AUTOSAR XML (schema 00044)
package /E40_Platform_System_SystemPackage/Components
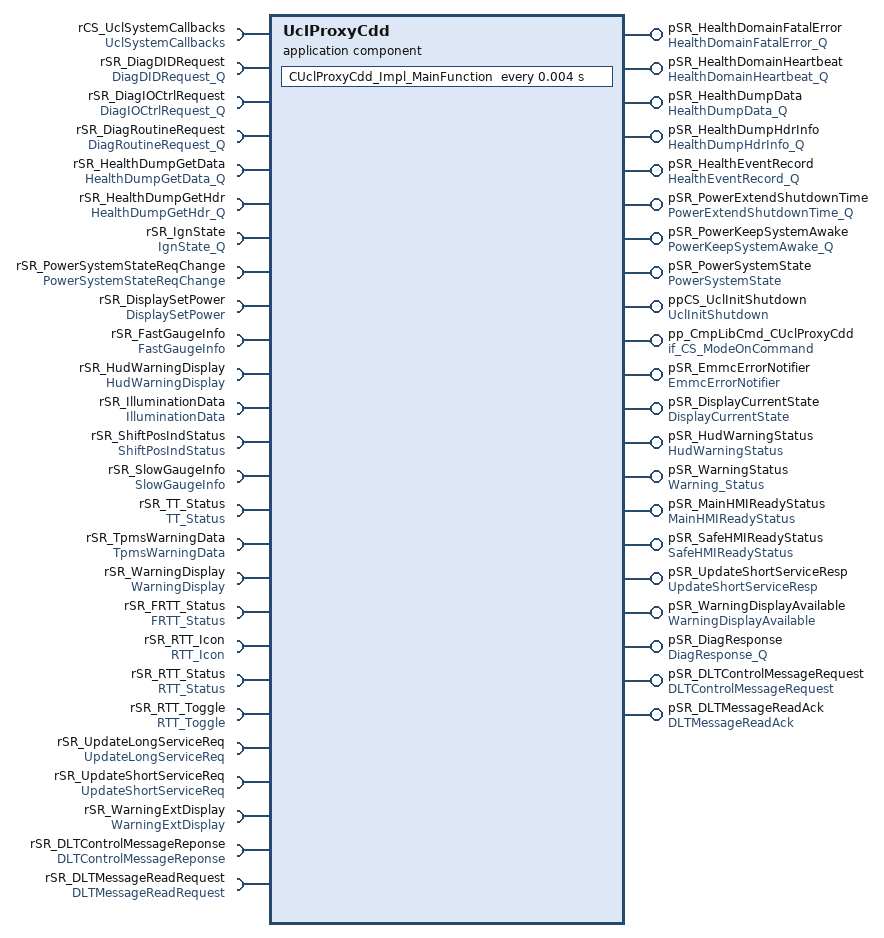
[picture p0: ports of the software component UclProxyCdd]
  application sw component type UclProxyCdd
    10 x provide port:
      pSR_HealthDomainFatalError: queued-sender-com-spec=HealthDomainFatalErrorData, provided-interface=HealthDomainFatalError_Q
      pSR_HealthDomainHeartbeat: queued-sender-com-spec=HealthDomainHeartbeatData, provided-interface=HealthDomainHeartbeat_Q
      pSR_HealthDumpData: queued-sender-com-spec=HealthDumpDataData, provided-interface=HealthDumpData_Q
      pSR_HealthDumpHdrInfo: queued-sender-com-spec=HealthDumpHdrInfoData, provided-interface=HealthDumpHdrInfo_Q
      pSR_HealthEventRecord: queued-sender-com-spec=HealthEventRecordData, provided-interface=HealthEventRecord_Q
      pSR_PowerExtendShutdownTime: queued-sender-com-spec=PowerExtendShutdownTimeData, provided-interface=PowerExtendShutdownTime_Q
      pSR_PowerKeepSystemAwake: queued-sender-com-spec=PowerKeepSystemAwakeData, provided-interface=PowerKeepSystemAwake_Q
      pSR_PowerSystemState: nonqueued-sender-com-spec{data-element=PowerSystemStateData, init-value=constant-reference=UclProxyCddPowerSystemStateDataValue0}, provided-interface=PowerSystemState
      ppCS_UclInitShutdown: provided-com-specs=[{operation=Impl_Initialize, queue-length=1}, {operation=Impl_Shutdown, queue-length=1}], provided-interface=UclInitShutdown
      pp_CmpLibCmd_CUclProxyCdd: server-com-spec{operation=Impl_OnCommand, queue-length=1}, provided-interface=if_CS_ModeOnCommand
    8 x require port:
      rCS_UclSystemCallbacks: required-com-specs=[ErrorNotification, LinkStatusChanged], required-interface=UclSystemCallbacks
      rSR_DiagDIDRequest: queued-receiver-com-spec{data-element=DiagDIDRequestData, queue-length=2}, required-interface=DiagDIDRequest_Q
      rSR_DiagIOCtrlRequest: queued-receiver-com-spec{data-element=DiagIOCtrlRequestData, queue-length=2}, required-interface=DiagIOCtrlRequest_Q
      rSR_DiagRoutineRequest: queued-receiver-com-spec{data-element=DiagRoutineRequestData, queue-length=2}, required-interface=DiagRoutineRequest_Q
      rSR_HealthDumpGetData: queued-receiver-com-spec{data-element=HealthDumpGetDataData, queue-length=1}, required-interface=HealthDumpGetData_Q
      rSR_HealthDumpGetHdr: queued-receiver-com-spec{data-element=HealthDumpGetHdrData, queue-length=1}, required-interface=HealthDumpGetHdr_Q
      rSR_IgnState: queued-receiver-com-spec{data-element=IgnStateData, queue-length=5}, required-interface=IgnState_Q
      rSR_PowerSystemStateReqChange: nonqueued-receiver-com-spec{data-element=PowerSystemStateReqChangeData, filter=data-filter-type=ALWAYS, init-value=constant-reference=UclProxyCddPowerSystemStateReqChangeDataValue0}, required-interface=PowerSystemStateReqChange
    provide port pSR_EmmcErrorNotifier: nonqueued-sender-com-spec{data-element=EmmcErrorNotifierData, init-value=constant-reference=UclProxyCddEmmcErrorNotifierDataValue0}, provided-interface=EmmcErrorNotifier
    provide port pSR_DisplayCurrentState: nonqueued-sender-com-spec{data-element=DisplayCurrentStateData, init-value=constant-reference=UclProxyCddDisplayCurrentStateDataValue0}, provided-interface=DisplayCurrentState
    require port rSR_DisplaySetPower: nonqueued-receiver-com-spec{data-element=DisplaySetPowerData, filter=data-filter-type=ALWAYS, init-value=constant-reference=UclProxyCddDisplaySetPowerDataValue0}, required-interface=DisplaySetPower
    provide port pSR_HudWarningStatus: nonqueued-sender-com-spec{data-element=HudWarningStatusData, init-value=constant-reference=UclProxyCddHudWarningStatusDataValue0}, provided-interface=HudWarningStatus
    provide port pSR_WarningStatus: nonqueued-sender-com-spec{data-element=WarningStatusData, init-value=constant-reference=UclProxyCddWarningStatusDataValue0}, provided-interface=Warning_Status
    8 x require port:
      rSR_FastGaugeInfo: nonqueued-receiver-com-spec{data-element=FastGaugeInfoData, filter=data-filter-type=ALWAYS, init-value=constant-reference=SFastGaugeInfo_InitValue}, required-interface=FastGaugeInfo
      rSR_HudWarningDisplay: nonqueued-receiver-com-spec{data-element=HudWarningDisplayData, filter=data-filter-type=ALWAYS, init-value=constant-reference=UclProxyCddHudWarningDisplayDataValue0}, required-interface=HudWarningDisplay
      rSR_IlluminationData: nonqueued-receiver-com-spec{data-element=IlluminationDataData, filter=data-filter-type=ALWAYS, init-value=constant-reference=UclProxyCddIlluminationDataDataValue0}, required-interface=IlluminationData
      rSR_ShiftPosIndStatus: nonqueued-receiver-com-spec{data-element=ShiftPosIndStatusData, filter=data-filter-type=ALWAYS, init-value=constant-reference=UclProxyCddShiftPosIndStatusDataValue0}, required-interface=ShiftPosIndStatus
      rSR_SlowGaugeInfo: nonqueued-receiver-com-spec{data-element=SlowGaugeInfoData, filter=data-filter-type=ALWAYS, init-value=constant-reference=UclProxyCddSlowGaugeInfoDataValue0}, required-interface=SlowGaugeInfo
      rSR_TT_Status: nonqueued-receiver-com-spec{data-element=TT_StatusData, filter=data-filter-type=ALWAYS, init-value=constant-reference=UclProxyCddTT_StatusDataValue0}, required-interface=TT_Status
      rSR_TpmsWarningData: nonqueued-receiver-com-spec{data-element=TpmsWarningDataData, filter=data-filter-type=ALWAYS, init-value=constant-reference=UclProxyCddTpmsWarningDataDataValue0}, required-interface=TpmsWarningData
      rSR_WarningDisplay: nonqueued-receiver-com-spec{data-element=WarningDisplayData, filter=data-filter-type=ALWAYS, init-value=constant-reference=UclProxyCddWarningDisplayDataValue0}, required-interface=WarningDisplay
    4 x provide port:
      pSR_MainHMIReadyStatus: queued-sender-com-spec=MainHMIReadyStatusData, provided-interface=MainHMIReadyStatus
      pSR_SafeHMIReadyStatus: queued-sender-com-spec=SafeHMIReadyStatusData, provided-interface=SafeHMIReadyStatus
      pSR_UpdateShortServiceResp: queued-sender-com-spec=UpdateShortServiceRespData, provided-interface=UpdateShortServiceResp
      pSR_WarningDisplayAvailable: nonqueued-sender-com-spec{data-element=WarningDisplayAvailableData, init-value=constant-reference=UclProxyCddWarningDisplayAvailableDataValue0}, provided-interface=WarningDisplayAvailable
    7 x require port:
      rSR_FRTT_Status: nonqueued-receiver-com-spec{data-element=FRTT_StatusData, filter=data-filter-type=ALWAYS, init-value=constant-reference=UclProxyCddFRTT_StatusDataValue0}, required-interface=FRTT_Status
      rSR_RTT_Icon: nonqueued-receiver-com-spec{data-element=RTT_IconData, filter=data-filter-type=ALWAYS, init-value=constant-reference=UclProxyCddRTT_IconDataValue0}, required-interface=RTT_Icon
      rSR_RTT_Status: nonqueued-receiver-com-spec{data-element=RTT_StatusData, filter=data-filter-type=ALWAYS, init-value=constant-reference=UclProxyCddRTT_StatusDataValue0}, required-interface=RTT_Status
      rSR_RTT_Toggle: nonqueued-receiver-com-spec{data-element=RTT_ToggleData, filter=data-filter-type=ALWAYS, init-value=constant-reference=UclProxyCddRTT_ToggleDataValue0}, required-interface=RTT_Toggle
      rSR_UpdateLongServiceReq: queued-receiver-com-spec{data-element=UpdateLongServiceReqData, queue-length=2}, required-interface=UpdateLongServiceReq
      rSR_UpdateShortServiceReq: queued-receiver-com-spec{data-element=UpdateShortServiceReqData, queue-length=2}, required-interface=UpdateShortServiceReq
      rSR_WarningExtDisplay: nonqueued-receiver-com-spec{data-element=WarningExtDisplayData, filter=data-filter-type=ALWAYS, init-value=constant-reference=UclProxyCddWarningExtDisplayDataValue0}, required-interface=WarningExtDisplay
    provide port pSR_DiagResponse: queued-sender-com-spec=DiagResponseData, provided-interface=DiagResponse_Q
    provide port pSR_DLTControlMessageRequest: nonqueued-sender-com-spec{data-element=DLTControlMessageRequestData, init-value=constant-reference=UclProxyCddDLTControlMessageRequestDataValue0}, provided-interface=DLTControlMessageRequest
    provide port pSR_DLTMessageReadAck: nonqueued-sender-com-spec{data-element=DLTMessageReadAckData, init-value=constant-reference=UclProxyCddDLTMessageReadAckDataValue0}, provided-interface=DLTMessageReadAck
    require port rSR_DLTControlMessageReponse: nonqueued-receiver-com-spec{data-element=DLTControlMessageReponseData, init-value=constant-reference=UclProxyCddDLTControlMessageReponseDataValue0}, required-interface=DLTControlMessageReponse
    require port rSR_DLTMessageReadRequest: nonqueued-receiver-com-spec{data-element=DLTMessageReadRequestData, init-value=constant-reference=UclProxyCddDLTMessageReadRequestDataValue0}, required-interface=DLTMessageReadRequest
    behavior IB_UclProxyCdd
      operation invoked event OIE_ppCS_UclInitShutdown_CUclProxyCdd_Impl_InitializeTrigByImpl_Initialize: start-on-event=CUclProxyCdd_Impl_Initialize, operation=ppCS_UclInitShutdown.Impl_Initialize
      timing event TECUclProxyCdd_Impl_MainFunction: start-on-event=CUclProxyCdd_Impl_MainFunction, period=0.004
      operation invoked event OIE_pp_CmpLibCmd_CUclProxyCdd_CUclProxyCdd_Impl_OnCommandTrigByImpl_OnCommand: start-on-event=CUclProxyCdd_Impl_OnCommand, operation=pp_CmpLibCmd_CUclProxyCdd.Impl_OnCommand
      operation invoked event OIE_ppCS_UclInitShutdown_CUclProxyCdd_Impl_ShutdownTrigByImpl_Shutdown: start-on-event=CUclProxyCdd_Impl_Shutdown, operation=ppCS_UclInitShutdown.Impl_Shutdown
      22 x data received event:
        DREOnDre_HealthDumpGetDataTrigByHealthDumpGetDataData: start-on-event=OnDre_HealthDumpGetData, data=rSR_HealthDumpGetData.HealthDumpGetDataData
        DREOnDre_HealthDumpGetHdrTrigByHealthDumpGetHdrData: start-on-event=OnDre_HealthDumpGetHdr, data=rSR_HealthDumpGetHdr.HealthDumpGetHdrData
        DREOnDre_PowerSystemStateReqChangeTrigByPowerSystemStateReqChangeData: start-on-event=OnDre_PowerSystemStateReqChange, data=rSR_PowerSystemStateReqChange.PowerSystemStateReqChangeData
        DREOnDre_DisplaySetPowerTrigByDisplaySetPowerData: start-on-event=OnDre_DisplaySetPower, data=rSR_DisplaySetPower.DisplaySetPowerData
        DREOnDre_FRTT_StatusTrigByFRTT_StatusData: start-on-event=OnDre_FRTT_Status, data=rSR_FRTT_Status.FRTT_StatusData
        DREOnDre_FastGaugeInfoTrigByFastGaugeInfoData: start-on-event=OnDre_FastGaugeInfo, data=rSR_FastGaugeInfo.FastGaugeInfoData
        DREOnDre_RTT_IconTrigByRTT_IconData: start-on-event=OnDre_RTT_Icon, data=rSR_RTT_Icon.RTT_IconData
        DREOnDre_RTT_StatusTrigByRTT_StatusData: start-on-event=OnDre_RTT_Status, data=rSR_RTT_Status.RTT_StatusData
        DREOnDre_RTT_ToggleTrigByRTT_ToggleData: start-on-event=OnDre_RTT_Toggle, data=rSR_RTT_Toggle.RTT_ToggleData
        DREOnDre_ShiftPosIndStatusTrigByShiftPosIndStatusData: start-on-event=OnDre_ShiftPosIndStatus, data=rSR_ShiftPosIndStatus.ShiftPosIndStatusData
        DREOnDre_SlowGaugeInfoTrigBySlowGaugeInfoData: start-on-event=OnDre_SlowGaugeInfo, data=rSR_SlowGaugeInfo.SlowGaugeInfoData
        DREOnDre_TT_StatusTrigByTT_StatusData: start-on-event=OnDre_TT_Status, data=rSR_TT_Status.TT_StatusData
        DREOnDre_WarningDisplayTrigByWarningDisplayData: start-on-event=OnDre_WarningDisplay, data=rSR_WarningDisplay.WarningDisplayData
        DREOnDre_DiagDIDRequestTrigByDiagDIDRequestData: start-on-event=OnDre_DiagDIDRequest, data=rSR_DiagDIDRequest.DiagDIDRequestData
        DREOnDre_DiagIOCtrlRequestTrigByDiagIOCtrlRequestData: start-on-event=OnDre_DiagIOCtrlRequest, data=rSR_DiagIOCtrlRequest.DiagIOCtrlRequestData
        DREOnDre_DiagRoutineRequestTrigByDiagRoutineRequestData: start-on-event=OnDre_DiagRoutineRequest, data=rSR_DiagRoutineRequest.DiagRoutineRequestData
        DREOnDre_IlluminationDataTrigByIlluminationDataData: start-on-event=OnDre_IlluminationData, data=rSR_IlluminationData.IlluminationDataData
        DREOnDre_UpdateLongServiceReqTrigByUpdateLongServiceReqData: start-on-event=OnDre_UpdateLongServiceReq, data=rSR_UpdateLongServiceReq.UpdateLongServiceReqData
        DREOnDre_UpdateShortServiceReqTrigByUpdateShortServiceReqData: start-on-event=OnDre_UpdateShortServiceReq, data=rSR_UpdateShortServiceReq.UpdateShortServiceReqData
        DREOnDre_WarningExtDisplayTrigByWarningExtDisplayData: start-on-event=OnDre_WarningExtDisplay, data=rSR_WarningExtDisplay.WarningExtDisplayData
        DREOnDre_DLTControlMessageReponseTrigByDLTControlMessageReponseData: start-on-event=OnDre_DLTControlMessageReponse, data=rSR_DLTControlMessageReponse.DLTControlMessageReponseData
        DREOnDre_DLTMessageReadRequestTrigByDLTMessageReadRequestData: start-on-event=OnDre_DLTMessageReadRequest, data=rSR_DLTMessageReadRequest.DLTMessageReadRequestData
      port-api-options:
        enable-take-address=false, error-handling=NO-TRANSFORMER-ERROR-HANDLING, indirect-api=false, port=pSR_HealthDomainFatalError
        enable-take-address=false, error-handling=NO-TRANSFORMER-ERROR-HANDLING, indirect-api=false, port=pSR_HealthDomainHeartbeat
        enable-take-address=false, error-handling=NO-TRANSFORMER-ERROR-HANDLING, indirect-api=false, port=pSR_HealthDumpData
        enable-take-address=false, error-handling=NO-TRANSFORMER-ERROR-HANDLING, indirect-api=false, port=pSR_HealthDumpHdrInfo
        enable-take-address=false, error-handling=NO-TRANSFORMER-ERROR-HANDLING, indirect-api=false, port=pSR_HealthEventRecord
        enable-take-address=false, error-handling=NO-TRANSFORMER-ERROR-HANDLING, indirect-api=false, port=pSR_PowerExtendShutdownTime
        enable-take-address=false, error-handling=NO-TRANSFORMER-ERROR-HANDLING, indirect-api=false, port=pSR_PowerKeepSystemAwake
        enable-take-address=false, error-handling=NO-TRANSFORMER-ERROR-HANDLING, indirect-api=false, port=pSR_PowerSystemState
        enable-take-address=false, error-handling=NO-TRANSFORMER-ERROR-HANDLING, indirect-api=false, port=ppCS_UclInitShutdown
        enable-take-address=false, error-handling=NO-TRANSFORMER-ERROR-HANDLING, indirect-api=false, port=pp_CmpLibCmd_CUclProxyCdd
        enable-take-address=false, error-handling=NO-TRANSFORMER-ERROR-HANDLING, indirect-api=false, port=rCS_UclSystemCallbacks
        enable-take-address=false, error-handling=NO-TRANSFORMER-ERROR-HANDLING, indirect-api=false, port=rSR_DiagDIDRequest
        enable-take-address=false, error-handling=NO-TRANSFORMER-ERROR-HANDLING, indirect-api=false, port=rSR_DiagIOCtrlRequest
        enable-take-address=false, error-handling=NO-TRANSFORMER-ERROR-HANDLING, indirect-api=false, port=rSR_DiagRoutineRequest
        enable-take-address=false, error-handling=NO-TRANSFORMER-ERROR-HANDLING, indirect-api=false, port=rSR_HealthDumpGetData
        enable-take-address=false, error-handling=NO-TRANSFORMER-ERROR-HANDLING, indirect-api=false, port=rSR_HealthDumpGetHdr
        enable-take-address=false, error-handling=NO-TRANSFORMER-ERROR-HANDLING, indirect-api=false, port=rSR_IgnState
        enable-take-address=false, error-handling=NO-TRANSFORMER-ERROR-HANDLING, indirect-api=false, port=rSR_PowerSystemStateReqChange
        enable-take-address=false, error-handling=NO-TRANSFORMER-ERROR-HANDLING, indirect-api=false, port=pSR_EmmcErrorNotifier
        enable-take-address=false, error-handling=NO-TRANSFORMER-ERROR-HANDLING, indirect-api=false, port=pSR_DisplayCurrentState
        enable-take-address=false, error-handling=NO-TRANSFORMER-ERROR-HANDLING, indirect-api=false, port=rSR_DisplaySetPower
        enable-take-address=false, error-handling=NO-TRANSFORMER-ERROR-HANDLING, indirect-api=false, port=pSR_HudWarningStatus
        enable-take-address=false, error-handling=NO-TRANSFORMER-ERROR-HANDLING, indirect-api=false, port=pSR_WarningStatus
        enable-take-address=false, error-handling=NO-TRANSFORMER-ERROR-HANDLING, indirect-api=false, port=rSR_FastGaugeInfo
        enable-take-address=false, error-handling=NO-TRANSFORMER-ERROR-HANDLING, indirect-api=false, port=rSR_HudWarningDisplay
        enable-take-address=false, error-handling=NO-TRANSFORMER-ERROR-HANDLING, indirect-api=false, port=rSR_IlluminationData
        enable-take-address=false, error-handling=NO-TRANSFORMER-ERROR-HANDLING, indirect-api=false, port=rSR_ShiftPosIndStatus
        enable-take-address=false, error-handling=NO-TRANSFORMER-ERROR-HANDLING, indirect-api=false, port=rSR_SlowGaugeInfo
        enable-take-address=false, error-handling=NO-TRANSFORMER-ERROR-HANDLING, indirect-api=false, port=rSR_TT_Status
        enable-take-address=false, error-handling=NO-TRANSFORMER-ERROR-HANDLING, indirect-api=false, port=rSR_TpmsWarningData
        enable-take-address=false, error-handling=NO-TRANSFORMER-ERROR-HANDLING, indirect-api=false, port=rSR_WarningDisplay
        enable-take-address=false, error-handling=NO-TRANSFORMER-ERROR-HANDLING, indirect-api=false, port=pSR_MainHMIReadyStatus
        enable-take-address=false, error-handling=NO-TRANSFORMER-ERROR-HANDLING, indirect-api=false, port=pSR_SafeHMIReadyStatus
        enable-take-address=false, error-handling=NO-TRANSFORMER-ERROR-HANDLING, indirect-api=false, port=pSR_UpdateShortServiceResp
        enable-take-address=false, error-handling=NO-TRANSFORMER-ERROR-HANDLING, indirect-api=false, port=pSR_WarningDisplayAvailable
        enable-take-address=false, error-handling=NO-TRANSFORMER-ERROR-HANDLING, indirect-api=false, port=rSR_FRTT_Status
        enable-take-address=false, error-handling=NO-TRANSFORMER-ERROR-HANDLING, indirect-api=false, port=rSR_RTT_Icon
        enable-take-address=false, error-handling=NO-TRANSFORMER-ERROR-HANDLING, indirect-api=false, port=rSR_RTT_Status
        enable-take-address=false, error-handling=NO-TRANSFORMER-ERROR-HANDLING, indirect-api=false, port=rSR_RTT_Toggle
        enable-take-address=false, error-handling=NO-TRANSFORMER-ERROR-HANDLING, indirect-api=false, port=rSR_UpdateLongServiceReq
        enable-take-address=false, error-handling=NO-TRANSFORMER-ERROR-HANDLING, indirect-api=false, port=rSR_UpdateShortServiceReq
        enable-take-address=false, error-handling=NO-TRANSFORMER-ERROR-HANDLING, indirect-api=false, port=rSR_WarningExtDisplay
        enable-take-address=false, error-handling=NO-TRANSFORMER-ERROR-HANDLING, indirect-api=false, port=pSR_DiagResponse
        enable-take-address=false, indirect-api=false, port=pSR_DLTControlMessageRequest
        enable-take-address=false, indirect-api=false, port=pSR_DLTMessageReadAck
        enable-take-address=false, indirect-api=false, port=rSR_DLTControlMessageReponse
        enable-take-address=false, indirect-api=false, port=rSR_DLTMessageReadRequest
      26 x runnable, all with can-be-invoked-concurrently=true:
        CUclProxyCdd_Impl_Initialize
        CUclProxyCdd_Impl_MainFunction
          data-receive-point-by-arguments:
            25 x access:
              DRP_rSR_DiagDIDRequest_DiagDIDRequestData: accessed-variable=rSR_DiagDIDRequest.DiagDIDRequestData
              DRP_rSR_DiagIOCtrlRequest_DiagIOCtrlRequestData: accessed-variable=rSR_DiagIOCtrlRequest.DiagIOCtrlRequestData
              DRP_rSR_DiagRoutineRequest_DiagRoutineRequestData: accessed-variable=rSR_DiagRoutineRequest.DiagRoutineRequestData
              DRP_rSR_HealthDumpGetData_HealthDumpGetDataData: accessed-variable=rSR_HealthDumpGetData.HealthDumpGetDataData
              DRP_rSR_HealthDumpGetHdr_HealthDumpGetHdrData: accessed-variable=rSR_HealthDumpGetHdr.HealthDumpGetHdrData
              DRP_rSR_IgnState_IgnStateData: accessed-variable=rSR_IgnState.IgnStateData
              DRA_rSR_PowerSystemStateReqChange_PowerSystemStateReqChangeData: accessed-variable=rSR_PowerSystemStateReqChange.PowerSystemStateReqChangeData
              DRA_rSR_DisplaySetPower_DisplaySetPowerData: accessed-variable=rSR_DisplaySetPower.DisplaySetPowerData
              DRA_rSR_FastGaugeInfo_FastGaugeInfoData: accessed-variable=rSR_FastGaugeInfo.FastGaugeInfoData
              DRA_rSR_HudWarningDisplay_HudWarningDisplayData: accessed-variable=rSR_HudWarningDisplay.HudWarningDisplayData
              DRA_rSR_IlluminationData_IlluminationDataData: accessed-variable=rSR_IlluminationData.IlluminationDataData
              DRA_rSR_ShiftPosIndStatus_ShiftPosIndStatusData: accessed-variable=rSR_ShiftPosIndStatus.ShiftPosIndStatusData
              DRA_rSR_SlowGaugeInfo_SlowGaugeInfoData: accessed-variable=rSR_SlowGaugeInfo.SlowGaugeInfoData
              DRA_rSR_TT_Status_TT_StatusData: accessed-variable=rSR_TT_Status.TT_StatusData
              DRA_rSR_TpmsWarningData_TpmsWarningDataData: accessed-variable=rSR_TpmsWarningData.TpmsWarningDataData
              DRA_rSR_WarningDisplay_WarningDisplayData: accessed-variable=rSR_WarningDisplay.WarningDisplayData
              DRA_rSR_FRTT_Status_FRTT_StatusData: accessed-variable=rSR_FRTT_Status.FRTT_StatusData
              DRA_rSR_RTT_Icon_RTT_IconData: accessed-variable=rSR_RTT_Icon.RTT_IconData
              DRA_rSR_RTT_Status_RTT_StatusData: accessed-variable=rSR_RTT_Status.RTT_StatusData
              DRA_rSR_RTT_Toggle_RTT_ToggleData: accessed-variable=rSR_RTT_Toggle.RTT_ToggleData
              DRA_rSR_WarningExtDisplay_WarningExtDisplayData: accessed-variable=rSR_WarningExtDisplay.WarningExtDisplayData
              DRP_rSR_UpdateLongServiceReq_UpdateLongServiceReqData: accessed-variable=rSR_UpdateLongServiceReq.UpdateLongServiceReqData
              DRP_rSR_UpdateShortServiceReq_UpdateShortServiceReqData: accessed-variable=rSR_UpdateShortServiceReq.UpdateShortServiceReqData
              DRA_rSR_DLTControlMessageReponse_DLTControlMessageReponseData: accessed-variable=rSR_DLTControlMessageReponse.DLTControlMessageReponseData
              DRA_rSR_DLTMessageReadRequest_DLTMessageReadRequestData: accessed-variable=rSR_DLTMessageReadRequest.DLTMessageReadRequestData
          data-send-points:
            19 x access:
              DSP_pSR_HealthDomainFatalError_HealthDomainFatalErrorData: accessed-variable=pSR_HealthDomainFatalError.HealthDomainFatalErrorData
              DSP_pSR_HealthDomainHeartbeat_HealthDomainHeartbeatData: accessed-variable=pSR_HealthDomainHeartbeat.HealthDomainHeartbeatData
              DSP_pSR_HealthDumpData_HealthDumpDataData: accessed-variable=pSR_HealthDumpData.HealthDumpDataData
              DSP_pSR_HealthDumpHdrInfo_HealthDumpHdrInfoData: accessed-variable=pSR_HealthDumpHdrInfo.HealthDumpHdrInfoData
              DSP_pSR_HealthEventRecord_HealthEventRecordData: accessed-variable=pSR_HealthEventRecord.HealthEventRecordData
              DSP_pSR_PowerExtendShutdownTime_PowerExtendShutdownTimeData: accessed-variable=pSR_PowerExtendShutdownTime.PowerExtendShutdownTimeData
              DSP_pSR_PowerKeepSystemAwake_PowerKeepSystemAwakeData: accessed-variable=pSR_PowerKeepSystemAwake.PowerKeepSystemAwakeData
              DWA_pSR_PowerSystemState_PowerSystemStateData: accessed-variable=pSR_PowerSystemState.PowerSystemStateData
              DWA_pSR_EmmcErrorNotifier_EmmcErrorNotifierData: accessed-variable=pSR_EmmcErrorNotifier.EmmcErrorNotifierData
              DWA_pSR_DisplayCurrentState_DisplayCurrentStateData: accessed-variable=pSR_DisplayCurrentState.DisplayCurrentStateData
              DWA_pSR_HudWarningStatus_HudWarningStatusData: accessed-variable=pSR_HudWarningStatus.HudWarningStatusData
              DWA_pSR_WarningStatus_WarningStatusData: accessed-variable=pSR_WarningStatus.WarningStatusData
              DWA_pSR_WarningDisplayAvailable_WarningDisplayAvailableData: accessed-variable=pSR_WarningDisplayAvailable.WarningDisplayAvailableData
              DSP_pSR_MainHMIReadyStatus_MainHMIReadyStatusData: accessed-variable=pSR_MainHMIReadyStatus.MainHMIReadyStatusData
              DSP_pSR_SafeHMIReadyStatus_SafeHMIReadyStatusData: accessed-variable=pSR_SafeHMIReadyStatus.SafeHMIReadyStatusData
              DSP_pSR_DiagResponse_DiagResponseData: accessed-variable=pSR_DiagResponse.DiagResponseData
              DSP_pSR_UpdateShortServiceResp_UpdateShortServiceRespData: accessed-variable=pSR_UpdateShortServiceResp.UpdateShortServiceRespData
              DWA_pSR_DLTControlMessageRequest_DLTControlMessageRequestData: accessed-variable=pSR_DLTControlMessageRequest.DLTControlMessageRequestData
              DWA_pSR_DLTMessageReadAck_DLTMessageReadAckData: accessed-variable=pSR_DLTMessageReadAck.DLTMessageReadAckData
          sync call OA_rCS_UclSystemCallbacks_ErrorNotification: operation=rCS_UclSystemCallbacks.ErrorNotification
          sync call OA_rCS_UclSystemCallbacks_LinkStatusChanged: operation=rCS_UclSystemCallbacks.LinkStatusChanged
        CUclProxyCdd_Impl_OnCommand
        CUclProxyCdd_Impl_Shutdown
        OnDre_HealthDumpGetData
          data-receive-point-by-arguments:
            25 x access:
              DRP_rSR_DiagDIDRequest_DiagDIDRequestData: accessed-variable=rSR_DiagDIDRequest.DiagDIDRequestData
              DRP_rSR_DiagIOCtrlRequest_DiagIOCtrlRequestData: accessed-variable=rSR_DiagIOCtrlRequest.DiagIOCtrlRequestData
              DRP_rSR_DiagRoutineRequest_DiagRoutineRequestData: accessed-variable=rSR_DiagRoutineRequest.DiagRoutineRequestData
              DRP_rSR_HealthDumpGetData_HealthDumpGetDataData: accessed-variable=rSR_HealthDumpGetData.HealthDumpGetDataData
              DRP_rSR_HealthDumpGetHdr_HealthDumpGetHdrData: accessed-variable=rSR_HealthDumpGetHdr.HealthDumpGetHdrData
              DRP_rSR_IgnState_IgnStateData: accessed-variable=rSR_IgnState.IgnStateData
              DRA_rSR_PowerSystemStateReqChange_PowerSystemStateReqChangeData: accessed-variable=rSR_PowerSystemStateReqChange.PowerSystemStateReqChangeData
              DRA_rSR_DisplaySetPower_DisplaySetPowerData: accessed-variable=rSR_DisplaySetPower.DisplaySetPowerData
              DRA_rSR_FastGaugeInfo_FastGaugeInfoData: accessed-variable=rSR_FastGaugeInfo.FastGaugeInfoData
              DRA_rSR_HudWarningDisplay_HudWarningDisplayData: accessed-variable=rSR_HudWarningDisplay.HudWarningDisplayData
              DRA_rSR_IlluminationData_IlluminationDataData: accessed-variable=rSR_IlluminationData.IlluminationDataData
              DRA_rSR_ShiftPosIndStatus_ShiftPosIndStatusData: accessed-variable=rSR_ShiftPosIndStatus.ShiftPosIndStatusData
              DRA_rSR_SlowGaugeInfo_SlowGaugeInfoData: accessed-variable=rSR_SlowGaugeInfo.SlowGaugeInfoData
              DRA_rSR_TT_Status_TT_StatusData: accessed-variable=rSR_TT_Status.TT_StatusData
              DRA_rSR_TpmsWarningData_TpmsWarningDataData: accessed-variable=rSR_TpmsWarningData.TpmsWarningDataData
              DRA_rSR_WarningDisplay_WarningDisplayData: accessed-variable=rSR_WarningDisplay.WarningDisplayData
              DRA_rSR_FRTT_Status_FRTT_StatusData: accessed-variable=rSR_FRTT_Status.FRTT_StatusData
              DRA_rSR_RTT_Icon_RTT_IconData: accessed-variable=rSR_RTT_Icon.RTT_IconData
              DRA_rSR_RTT_Status_RTT_StatusData: accessed-variable=rSR_RTT_Status.RTT_StatusData
              DRA_rSR_RTT_Toggle_RTT_ToggleData: accessed-variable=rSR_RTT_Toggle.RTT_ToggleData
              DRA_rSR_WarningExtDisplay_WarningExtDisplayData: accessed-variable=rSR_WarningExtDisplay.WarningExtDisplayData
              DRP_rSR_UpdateLongServiceReq_UpdateLongServiceReqData: accessed-variable=rSR_UpdateLongServiceReq.UpdateLongServiceReqData
              DRP_rSR_UpdateShortServiceReq_UpdateShortServiceReqData: accessed-variable=rSR_UpdateShortServiceReq.UpdateShortServiceReqData
              DRA_rSR_DLTControlMessageReponse_DLTControlMessageReponseData: accessed-variable=rSR_DLTControlMessageReponse.DLTControlMessageReponseData
              DRA_rSR_DLTMessageReadRequest_DLTMessageReadRequestData: accessed-variable=rSR_DLTMessageReadRequest.DLTMessageReadRequestData
          data-send-points:
            19 x access:
              DSP_pSR_HealthDomainFatalError_HealthDomainFatalErrorData: accessed-variable=pSR_HealthDomainFatalError.HealthDomainFatalErrorData
              DSP_pSR_HealthDomainHeartbeat_HealthDomainHeartbeatData: accessed-variable=pSR_HealthDomainHeartbeat.HealthDomainHeartbeatData
              DSP_pSR_HealthDumpData_HealthDumpDataData: accessed-variable=pSR_HealthDumpData.HealthDumpDataData
              DSP_pSR_HealthDumpHdrInfo_HealthDumpHdrInfoData: accessed-variable=pSR_HealthDumpHdrInfo.HealthDumpHdrInfoData
              DSP_pSR_HealthEventRecord_HealthEventRecordData: accessed-variable=pSR_HealthEventRecord.HealthEventRecordData
              DSP_pSR_PowerExtendShutdownTime_PowerExtendShutdownTimeData: accessed-variable=pSR_PowerExtendShutdownTime.PowerExtendShutdownTimeData
              DSP_pSR_PowerKeepSystemAwake_PowerKeepSystemAwakeData: accessed-variable=pSR_PowerKeepSystemAwake.PowerKeepSystemAwakeData
              DWA_pSR_PowerSystemState_PowerSystemStateData: accessed-variable=pSR_PowerSystemState.PowerSystemStateData
              DWA_pSR_EmmcErrorNotifier_EmmcErrorNotifierData: accessed-variable=pSR_EmmcErrorNotifier.EmmcErrorNotifierData
              DWA_pSR_DisplayCurrentState_DisplayCurrentStateData: accessed-variable=pSR_DisplayCurrentState.DisplayCurrentStateData
              DWA_pSR_HudWarningStatus_HudWarningStatusData: accessed-variable=pSR_HudWarningStatus.HudWarningStatusData
              DWA_pSR_WarningStatus_WarningStatusData: accessed-variable=pSR_WarningStatus.WarningStatusData
              DWA_pSR_WarningDisplayAvailable_WarningDisplayAvailableData: accessed-variable=pSR_WarningDisplayAvailable.WarningDisplayAvailableData
              DSP_pSR_MainHMIReadyStatus_MainHMIReadyStatusData: accessed-variable=pSR_MainHMIReadyStatus.MainHMIReadyStatusData
              DSP_pSR_SafeHMIReadyStatus_SafeHMIReadyStatusData: accessed-variable=pSR_SafeHMIReadyStatus.SafeHMIReadyStatusData
              DSP_pSR_DiagResponse_DiagResponseData: accessed-variable=pSR_DiagResponse.DiagResponseData
              DSP_pSR_UpdateShortServiceResp_UpdateShortServiceRespData: accessed-variable=pSR_UpdateShortServiceResp.UpdateShortServiceRespData
              DWA_pSR_DLTControlMessageRequest_DLTControlMessageRequestData: accessed-variable=pSR_DLTControlMessageRequest.DLTControlMessageRequestData
              DWA_pSR_DLTMessageReadAck_DLTMessageReadAckData: accessed-variable=pSR_DLTMessageReadAck.DLTMessageReadAckData
          sync call OA_rCS_UclSystemCallbacks_ErrorNotification: operation=rCS_UclSystemCallbacks.ErrorNotification
          sync call OA_rCS_UclSystemCallbacks_LinkStatusChanged: operation=rCS_UclSystemCallbacks.LinkStatusChanged
        OnDre_HealthDumpGetHdr
          data-receive-point-by-arguments:
            25 x access:
              DRP_rSR_DiagDIDRequest_DiagDIDRequestData: accessed-variable=rSR_DiagDIDRequest.DiagDIDRequestData
              DRP_rSR_DiagIOCtrlRequest_DiagIOCtrlRequestData: accessed-variable=rSR_DiagIOCtrlRequest.DiagIOCtrlRequestData
              DRP_rSR_DiagRoutineRequest_DiagRoutineRequestData: accessed-variable=rSR_DiagRoutineRequest.DiagRoutineRequestData
              DRP_rSR_HealthDumpGetData_HealthDumpGetDataData: accessed-variable=rSR_HealthDumpGetData.HealthDumpGetDataData
              DRP_rSR_HealthDumpGetHdr_HealthDumpGetHdrData: accessed-variable=rSR_HealthDumpGetHdr.HealthDumpGetHdrData
              DRP_rSR_IgnState_IgnStateData: accessed-variable=rSR_IgnState.IgnStateData
              DRA_rSR_PowerSystemStateReqChange_PowerSystemStateReqChangeData: accessed-variable=rSR_PowerSystemStateReqChange.PowerSystemStateReqChangeData
              DRA_rSR_DisplaySetPower_DisplaySetPowerData: accessed-variable=rSR_DisplaySetPower.DisplaySetPowerData
              DRA_rSR_FastGaugeInfo_FastGaugeInfoData: accessed-variable=rSR_FastGaugeInfo.FastGaugeInfoData
              DRA_rSR_HudWarningDisplay_HudWarningDisplayData: accessed-variable=rSR_HudWarningDisplay.HudWarningDisplayData
              DRA_rSR_IlluminationData_IlluminationDataData: accessed-variable=rSR_IlluminationData.IlluminationDataData
              DRA_rSR_ShiftPosIndStatus_ShiftPosIndStatusData: accessed-variable=rSR_ShiftPosIndStatus.ShiftPosIndStatusData
              DRA_rSR_SlowGaugeInfo_SlowGaugeInfoData: accessed-variable=rSR_SlowGaugeInfo.SlowGaugeInfoData
              DRA_rSR_TT_Status_TT_StatusData: accessed-variable=rSR_TT_Status.TT_StatusData
              DRA_rSR_TpmsWarningData_TpmsWarningDataData: accessed-variable=rSR_TpmsWarningData.TpmsWarningDataData
              DRA_rSR_WarningDisplay_WarningDisplayData: accessed-variable=rSR_WarningDisplay.WarningDisplayData
              DRA_rSR_FRTT_Status_FRTT_StatusData: accessed-variable=rSR_FRTT_Status.FRTT_StatusData
              DRA_rSR_RTT_Icon_RTT_IconData: accessed-variable=rSR_RTT_Icon.RTT_IconData
              DRA_rSR_RTT_Status_RTT_StatusData: accessed-variable=rSR_RTT_Status.RTT_StatusData
              DRA_rSR_RTT_Toggle_RTT_ToggleData: accessed-variable=rSR_RTT_Toggle.RTT_ToggleData
              DRA_rSR_WarningExtDisplay_WarningExtDisplayData: accessed-variable=rSR_WarningExtDisplay.WarningExtDisplayData
              DRP_rSR_UpdateLongServiceReq_UpdateLongServiceReqData: accessed-variable=rSR_UpdateLongServiceReq.UpdateLongServiceReqData
              DRP_rSR_UpdateShortServiceReq_UpdateShortServiceReqData: accessed-variable=rSR_UpdateShortServiceReq.UpdateShortServiceReqData
              DRA_rSR_DLTControlMessageReponse_DLTControlMessageReponseData: accessed-variable=rSR_DLTControlMessageReponse.DLTControlMessageReponseData
              DRA_rSR_DLTMessageReadRequest_DLTMessageReadRequestData: accessed-variable=rSR_DLTMessageReadRequest.DLTMessageReadRequestData
          data-send-points:
            19 x access:
              DSP_pSR_HealthDomainFatalError_HealthDomainFatalErrorData: accessed-variable=pSR_HealthDomainFatalError.HealthDomainFatalErrorData
              DSP_pSR_HealthDomainHeartbeat_HealthDomainHeartbeatData: accessed-variable=pSR_HealthDomainHeartbeat.HealthDomainHeartbeatData
              DSP_pSR_HealthDumpData_HealthDumpDataData: accessed-variable=pSR_HealthDumpData.HealthDumpDataData
              DSP_pSR_HealthDumpHdrInfo_HealthDumpHdrInfoData: accessed-variable=pSR_HealthDumpHdrInfo.HealthDumpHdrInfoData
              DSP_pSR_HealthEventRecord_HealthEventRecordData: accessed-variable=pSR_HealthEventRecord.HealthEventRecordData
              DSP_pSR_PowerExtendShutdownTime_PowerExtendShutdownTimeData: accessed-variable=pSR_PowerExtendShutdownTime.PowerExtendShutdownTimeData
              DSP_pSR_PowerKeepSystemAwake_PowerKeepSystemAwakeData: accessed-variable=pSR_PowerKeepSystemAwake.PowerKeepSystemAwakeData
              DWA_pSR_PowerSystemState_PowerSystemStateData: accessed-variable=pSR_PowerSystemState.PowerSystemStateData
              DWA_pSR_EmmcErrorNotifier_EmmcErrorNotifierData: accessed-variable=pSR_EmmcErrorNotifier.EmmcErrorNotifierData
              DWA_pSR_DisplayCurrentState_DisplayCurrentStateData: accessed-variable=pSR_DisplayCurrentState.DisplayCurrentStateData
              DWA_pSR_HudWarningStatus_HudWarningStatusData: accessed-variable=pSR_HudWarningStatus.HudWarningStatusData
              DWA_pSR_WarningStatus_WarningStatusData: accessed-variable=pSR_WarningStatus.WarningStatusData
              DWA_pSR_WarningDisplayAvailable_WarningDisplayAvailableData: accessed-variable=pSR_WarningDisplayAvailable.WarningDisplayAvailableData
              DSP_pSR_MainHMIReadyStatus_MainHMIReadyStatusData: accessed-variable=pSR_MainHMIReadyStatus.MainHMIReadyStatusData
              DSP_pSR_SafeHMIReadyStatus_SafeHMIReadyStatusData: accessed-variable=pSR_SafeHMIReadyStatus.SafeHMIReadyStatusData
              DSP_pSR_DiagResponse_DiagResponseData: accessed-variable=pSR_DiagResponse.DiagResponseData
              DSP_pSR_UpdateShortServiceResp_UpdateShortServiceRespData: accessed-variable=pSR_UpdateShortServiceResp.UpdateShortServiceRespData
              DWA_pSR_DLTControlMessageRequest_DLTControlMessageRequestData: accessed-variable=pSR_DLTControlMessageRequest.DLTControlMessageRequestData
              DWA_pSR_DLTMessageReadAck_DLTMessageReadAckData: accessed-variable=pSR_DLTMessageReadAck.DLTMessageReadAckData
          sync call OA_rCS_UclSystemCallbacks_ErrorNotification: operation=rCS_UclSystemCallbacks.ErrorNotification
          sync call OA_rCS_UclSystemCallbacks_LinkStatusChanged: operation=rCS_UclSystemCallbacks.LinkStatusChanged
        OnDre_PowerSystemStateReqChange
          data-receive-point-by-arguments:
            25 x access:
              DRP_rSR_DiagDIDRequest_DiagDIDRequestData: accessed-variable=rSR_DiagDIDRequest.DiagDIDRequestData
              DRP_rSR_DiagIOCtrlRequest_DiagIOCtrlRequestData: accessed-variable=rSR_DiagIOCtrlRequest.DiagIOCtrlRequestData
              DRP_rSR_DiagRoutineRequest_DiagRoutineRequestData: accessed-variable=rSR_DiagRoutineRequest.DiagRoutineRequestData
              DRP_rSR_HealthDumpGetData_HealthDumpGetDataData: accessed-variable=rSR_HealthDumpGetData.HealthDumpGetDataData
              DRP_rSR_HealthDumpGetHdr_HealthDumpGetHdrData: accessed-variable=rSR_HealthDumpGetHdr.HealthDumpGetHdrData
              DRP_rSR_IgnState_IgnStateData: accessed-variable=rSR_IgnState.IgnStateData
              DRA_rSR_PowerSystemStateReqChange_PowerSystemStateReqChangeData: accessed-variable=rSR_PowerSystemStateReqChange.PowerSystemStateReqChangeData
              DRA_rSR_DisplaySetPower_DisplaySetPowerData: accessed-variable=rSR_DisplaySetPower.DisplaySetPowerData
              DRA_rSR_FastGaugeInfo_FastGaugeInfoData: accessed-variable=rSR_FastGaugeInfo.FastGaugeInfoData
              DRA_rSR_HudWarningDisplay_HudWarningDisplayData: accessed-variable=rSR_HudWarningDisplay.HudWarningDisplayData
              DRA_rSR_IlluminationData_IlluminationDataData: accessed-variable=rSR_IlluminationData.IlluminationDataData
              DRA_rSR_ShiftPosIndStatus_ShiftPosIndStatusData: accessed-variable=rSR_ShiftPosIndStatus.ShiftPosIndStatusData
              DRA_rSR_SlowGaugeInfo_SlowGaugeInfoData: accessed-variable=rSR_SlowGaugeInfo.SlowGaugeInfoData
              DRA_rSR_TT_Status_TT_StatusData: accessed-variable=rSR_TT_Status.TT_StatusData
              DRA_rSR_TpmsWarningData_TpmsWarningDataData: accessed-variable=rSR_TpmsWarningData.TpmsWarningDataData
              DRA_rSR_WarningDisplay_WarningDisplayData: accessed-variable=rSR_WarningDisplay.WarningDisplayData
              DRA_rSR_FRTT_Status_FRTT_StatusData: accessed-variable=rSR_FRTT_Status.FRTT_StatusData
              DRA_rSR_RTT_Icon_RTT_IconData: accessed-variable=rSR_RTT_Icon.RTT_IconData
              DRA_rSR_RTT_Status_RTT_StatusData: accessed-variable=rSR_RTT_Status.RTT_StatusData
              DRA_rSR_RTT_Toggle_RTT_ToggleData: accessed-variable=rSR_RTT_Toggle.RTT_ToggleData
              DRA_rSR_WarningExtDisplay_WarningExtDisplayData: accessed-variable=rSR_WarningExtDisplay.WarningExtDisplayData
              DRP_rSR_UpdateLongServiceReq_UpdateLongServiceReqData: accessed-variable=rSR_UpdateLongServiceReq.UpdateLongServiceReqData
              DRP_rSR_UpdateShortServiceReq_UpdateShortServiceReqData: accessed-variable=rSR_UpdateShortServiceReq.UpdateShortServiceReqData
              DRA_rSR_DLTControlMessageReponse_DLTControlMessageReponseData: accessed-variable=rSR_DLTControlMessageReponse.DLTControlMessageReponseData
              DRA_rSR_DLTMessageReadRequest_DLTMessageReadRequestData: accessed-variable=rSR_DLTMessageReadRequest.DLTMessageReadRequestData
          data-send-points:
            19 x access:
              DSP_pSR_HealthDomainFatalError_HealthDomainFatalErrorData: accessed-variable=pSR_HealthDomainFatalError.HealthDomainFatalErrorData
              DSP_pSR_HealthDomainHeartbeat_HealthDomainHeartbeatData: accessed-variable=pSR_HealthDomainHeartbeat.HealthDomainHeartbeatData
              DSP_pSR_HealthDumpData_HealthDumpDataData: accessed-variable=pSR_HealthDumpData.HealthDumpDataData
              DSP_pSR_HealthDumpHdrInfo_HealthDumpHdrInfoData: accessed-variable=pSR_HealthDumpHdrInfo.HealthDumpHdrInfoData
              DSP_pSR_HealthEventRecord_HealthEventRecordData: accessed-variable=pSR_HealthEventRecord.HealthEventRecordData
              DSP_pSR_PowerExtendShutdownTime_PowerExtendShutdownTimeData: accessed-variable=pSR_PowerExtendShutdownTime.PowerExtendShutdownTimeData
              DSP_pSR_PowerKeepSystemAwake_PowerKeepSystemAwakeData: accessed-variable=pSR_PowerKeepSystemAwake.PowerKeepSystemAwakeData
              DWA_pSR_PowerSystemState_PowerSystemStateData: accessed-variable=pSR_PowerSystemState.PowerSystemStateData
              DWA_pSR_EmmcErrorNotifier_EmmcErrorNotifierData: accessed-variable=pSR_EmmcErrorNotifier.EmmcErrorNotifierData
              DWA_pSR_DisplayCurrentState_DisplayCurrentStateData: accessed-variable=pSR_DisplayCurrentState.DisplayCurrentStateData
              DWA_pSR_HudWarningStatus_HudWarningStatusData: accessed-variable=pSR_HudWarningStatus.HudWarningStatusData
              DWA_pSR_WarningStatus_WarningStatusData: accessed-variable=pSR_WarningStatus.WarningStatusData
              DWA_pSR_WarningDisplayAvailable_WarningDisplayAvailableData: accessed-variable=pSR_WarningDisplayAvailable.WarningDisplayAvailableData
              DSP_pSR_MainHMIReadyStatus_MainHMIReadyStatusData: accessed-variable=pSR_MainHMIReadyStatus.MainHMIReadyStatusData
              DSP_pSR_SafeHMIReadyStatus_SafeHMIReadyStatusData: accessed-variable=pSR_SafeHMIReadyStatus.SafeHMIReadyStatusData
              DSP_pSR_DiagResponse_DiagResponseData: accessed-variable=pSR_DiagResponse.DiagResponseData
              DSP_pSR_UpdateShortServiceResp_UpdateShortServiceRespData: accessed-variable=pSR_UpdateShortServiceResp.UpdateShortServiceRespData
              DWA_pSR_DLTControlMessageRequest_DLTControlMessageRequestData: accessed-variable=pSR_DLTControlMessageRequest.DLTControlMessageRequestData
              DWA_pSR_DLTMessageReadAck_DLTMessageReadAckData: accessed-variable=pSR_DLTMessageReadAck.DLTMessageReadAckData
          sync call OA_rCS_UclSystemCallbacks_ErrorNotification: operation=rCS_UclSystemCallbacks.ErrorNotification
          sync call OA_rCS_UclSystemCallbacks_LinkStatusChanged: operation=rCS_UclSystemCallbacks.LinkStatusChanged
        OnDre_DisplaySetPower
          data-receive-point-by-arguments:
            25 x access:
              DRP_rSR_DiagDIDRequest_DiagDIDRequestData: accessed-variable=rSR_DiagDIDRequest.DiagDIDRequestData
              DRP_rSR_DiagIOCtrlRequest_DiagIOCtrlRequestData: accessed-variable=rSR_DiagIOCtrlRequest.DiagIOCtrlRequestData
              DRP_rSR_DiagRoutineRequest_DiagRoutineRequestData: accessed-variable=rSR_DiagRoutineRequest.DiagRoutineRequestData
              DRA_rSR_DisplaySetPower_DisplaySetPowerData: accessed-variable=rSR_DisplaySetPower.DisplaySetPowerData
              DRP_rSR_HealthDumpGetData_HealthDumpGetDataData: accessed-variable=rSR_HealthDumpGetData.HealthDumpGetDataData
              DRP_rSR_HealthDumpGetHdr_HealthDumpGetHdrData: accessed-variable=rSR_HealthDumpGetHdr.HealthDumpGetHdrData
              DRP_rSR_IgnState_IgnStateData: accessed-variable=rSR_IgnState.IgnStateData
              DRA_rSR_PowerSystemStateReqChange_PowerSystemStateReqChangeData: accessed-variable=rSR_PowerSystemStateReqChange.PowerSystemStateReqChangeData
              DRA_rSR_FastGaugeInfo_FastGaugeInfoData: accessed-variable=rSR_FastGaugeInfo.FastGaugeInfoData
              DRA_rSR_HudWarningDisplay_HudWarningDisplayData: accessed-variable=rSR_HudWarningDisplay.HudWarningDisplayData
              DRA_rSR_IlluminationData_IlluminationDataData: accessed-variable=rSR_IlluminationData.IlluminationDataData
              DRA_rSR_ShiftPosIndStatus_ShiftPosIndStatusData: accessed-variable=rSR_ShiftPosIndStatus.ShiftPosIndStatusData
              DRA_rSR_SlowGaugeInfo_SlowGaugeInfoData: accessed-variable=rSR_SlowGaugeInfo.SlowGaugeInfoData
              DRA_rSR_TT_Status_TT_StatusData: accessed-variable=rSR_TT_Status.TT_StatusData
              DRA_rSR_TpmsWarningData_TpmsWarningDataData: accessed-variable=rSR_TpmsWarningData.TpmsWarningDataData
              DRA_rSR_WarningDisplay_WarningDisplayData: accessed-variable=rSR_WarningDisplay.WarningDisplayData
              DRA_rSR_FRTT_Status_FRTT_StatusData: accessed-variable=rSR_FRTT_Status.FRTT_StatusData
              DRA_rSR_RTT_Icon_RTT_IconData: accessed-variable=rSR_RTT_Icon.RTT_IconData
              DRA_rSR_RTT_Status_RTT_StatusData: accessed-variable=rSR_RTT_Status.RTT_StatusData
              DRA_rSR_RTT_Toggle_RTT_ToggleData: accessed-variable=rSR_RTT_Toggle.RTT_ToggleData
              DRA_rSR_WarningExtDisplay_WarningExtDisplayData: accessed-variable=rSR_WarningExtDisplay.WarningExtDisplayData
              DRP_rSR_UpdateLongServiceReq_UpdateLongServiceReqData: accessed-variable=rSR_UpdateLongServiceReq.UpdateLongServiceReqData
              DRP_rSR_UpdateShortServiceReq_UpdateShortServiceReqData: accessed-variable=rSR_UpdateShortServiceReq.UpdateShortServiceReqData
              DRA_rSR_DLTControlMessageReponse_DLTControlMessageReponseData: accessed-variable=rSR_DLTControlMessageReponse.DLTControlMessageReponseData
              DRA_rSR_DLTMessageReadRequest_DLTMessageReadRequestData: accessed-variable=rSR_DLTMessageReadRequest.DLTMessageReadRequestData
          data-send-points:
            19 x access:
              DWA_pSR_DisplayCurrentState_DisplayCurrentStateData: accessed-variable=pSR_DisplayCurrentState.DisplayCurrentStateData
              DWA_pSR_EmmcErrorNotifier_EmmcErrorNotifierData: accessed-variable=pSR_EmmcErrorNotifier.EmmcErrorNotifierData
              DSP_pSR_HealthDomainFatalError_HealthDomainFatalErrorData: accessed-variable=pSR_HealthDomainFatalError.HealthDomainFatalErrorData
              DSP_pSR_HealthDomainHeartbeat_HealthDomainHeartbeatData: accessed-variable=pSR_HealthDomainHeartbeat.HealthDomainHeartbeatData
              DSP_pSR_HealthDumpData_HealthDumpDataData: accessed-variable=pSR_HealthDumpData.HealthDumpDataData
              DSP_pSR_HealthDumpHdrInfo_HealthDumpHdrInfoData: accessed-variable=pSR_HealthDumpHdrInfo.HealthDumpHdrInfoData
              DSP_pSR_HealthEventRecord_HealthEventRecordData: accessed-variable=pSR_HealthEventRecord.HealthEventRecordData
              DSP_pSR_PowerExtendShutdownTime_PowerExtendShutdownTimeData: accessed-variable=pSR_PowerExtendShutdownTime.PowerExtendShutdownTimeData
              DSP_pSR_PowerKeepSystemAwake_PowerKeepSystemAwakeData: accessed-variable=pSR_PowerKeepSystemAwake.PowerKeepSystemAwakeData
              DWA_pSR_PowerSystemState_PowerSystemStateData: accessed-variable=pSR_PowerSystemState.PowerSystemStateData
              DWA_pSR_HudWarningStatus_HudWarningStatusData: accessed-variable=pSR_HudWarningStatus.HudWarningStatusData
              DWA_pSR_WarningStatus_WarningStatusData: accessed-variable=pSR_WarningStatus.WarningStatusData
              DWA_pSR_WarningDisplayAvailable_WarningDisplayAvailableData: accessed-variable=pSR_WarningDisplayAvailable.WarningDisplayAvailableData
              DSP_pSR_MainHMIReadyStatus_MainHMIReadyStatusData: accessed-variable=pSR_MainHMIReadyStatus.MainHMIReadyStatusData
              DSP_pSR_SafeHMIReadyStatus_SafeHMIReadyStatusData: accessed-variable=pSR_SafeHMIReadyStatus.SafeHMIReadyStatusData
              DSP_pSR_DiagResponse_DiagResponseData: accessed-variable=pSR_DiagResponse.DiagResponseData
              DSP_pSR_UpdateShortServiceResp_UpdateShortServiceRespData: accessed-variable=pSR_UpdateShortServiceResp.UpdateShortServiceRespData
              DWA_pSR_DLTControlMessageRequest_DLTControlMessageRequestData: accessed-variable=pSR_DLTControlMessageRequest.DLTControlMessageRequestData
              DWA_pSR_DLTMessageReadAck_DLTMessageReadAckData: accessed-variable=pSR_DLTMessageReadAck.DLTMessageReadAckData
          sync call OA_rCS_UclSystemCallbacks_ErrorNotification: operation=rCS_UclSystemCallbacks.ErrorNotification
          sync call OA_rCS_UclSystemCallbacks_LinkStatusChanged: operation=rCS_UclSystemCallbacks.LinkStatusChanged
        OnDre_FRTT_Status
          data-receive-point-by-arguments:
            25 x access:
              DRP_rSR_DiagDIDRequest_DiagDIDRequestData: accessed-variable=rSR_DiagDIDRequest.DiagDIDRequestData
              DRP_rSR_DiagIOCtrlRequest_DiagIOCtrlRequestData: accessed-variable=rSR_DiagIOCtrlRequest.DiagIOCtrlRequestData
              DRP_rSR_DiagRoutineRequest_DiagRoutineRequestData: accessed-variable=rSR_DiagRoutineRequest.DiagRoutineRequestData
              DRA_rSR_DisplaySetPower_DisplaySetPowerData: accessed-variable=rSR_DisplaySetPower.DisplaySetPowerData
              DRA_rSR_FRTT_Status_FRTT_StatusData: accessed-variable=rSR_FRTT_Status.FRTT_StatusData
              DRA_rSR_FastGaugeInfo_FastGaugeInfoData: accessed-variable=rSR_FastGaugeInfo.FastGaugeInfoData
              DRP_rSR_HealthDumpGetData_HealthDumpGetDataData: accessed-variable=rSR_HealthDumpGetData.HealthDumpGetDataData
              DRP_rSR_HealthDumpGetHdr_HealthDumpGetHdrData: accessed-variable=rSR_HealthDumpGetHdr.HealthDumpGetHdrData
              DRA_rSR_HudWarningDisplay_HudWarningDisplayData: accessed-variable=rSR_HudWarningDisplay.HudWarningDisplayData
              DRP_rSR_IgnState_IgnStateData: accessed-variable=rSR_IgnState.IgnStateData
              DRA_rSR_IlluminationData_IlluminationDataData: accessed-variable=rSR_IlluminationData.IlluminationDataData
              DRA_rSR_PowerSystemStateReqChange_PowerSystemStateReqChangeData: accessed-variable=rSR_PowerSystemStateReqChange.PowerSystemStateReqChangeData
              DRA_rSR_RTT_Icon_RTT_IconData: accessed-variable=rSR_RTT_Icon.RTT_IconData
              DRA_rSR_RTT_Status_RTT_StatusData: accessed-variable=rSR_RTT_Status.RTT_StatusData
              DRA_rSR_RTT_Toggle_RTT_ToggleData: accessed-variable=rSR_RTT_Toggle.RTT_ToggleData
              DRA_rSR_ShiftPosIndStatus_ShiftPosIndStatusData: accessed-variable=rSR_ShiftPosIndStatus.ShiftPosIndStatusData
              DRA_rSR_SlowGaugeInfo_SlowGaugeInfoData: accessed-variable=rSR_SlowGaugeInfo.SlowGaugeInfoData
              DRA_rSR_TT_Status_TT_StatusData: accessed-variable=rSR_TT_Status.TT_StatusData
              DRA_rSR_TpmsWarningData_TpmsWarningDataData: accessed-variable=rSR_TpmsWarningData.TpmsWarningDataData
              DRA_rSR_WarningDisplay_WarningDisplayData: accessed-variable=rSR_WarningDisplay.WarningDisplayData
              DRA_rSR_WarningExtDisplay_WarningExtDisplayData: accessed-variable=rSR_WarningExtDisplay.WarningExtDisplayData
              DRP_rSR_UpdateLongServiceReq_UpdateLongServiceReqData: accessed-variable=rSR_UpdateLongServiceReq.UpdateLongServiceReqData
              DRP_rSR_UpdateShortServiceReq_UpdateShortServiceReqData: accessed-variable=rSR_UpdateShortServiceReq.UpdateShortServiceReqData
              DRA_rSR_DLTControlMessageReponse_DLTControlMessageReponseData: accessed-variable=rSR_DLTControlMessageReponse.DLTControlMessageReponseData
              DRA_rSR_DLTMessageReadRequest_DLTMessageReadRequestData: accessed-variable=rSR_DLTMessageReadRequest.DLTMessageReadRequestData
          data-send-points:
            19 x access:
              DWA_pSR_DisplayCurrentState_DisplayCurrentStateData: accessed-variable=pSR_DisplayCurrentState.DisplayCurrentStateData
              DWA_pSR_EmmcErrorNotifier_EmmcErrorNotifierData: accessed-variable=pSR_EmmcErrorNotifier.EmmcErrorNotifierData
              DSP_pSR_HealthDomainFatalError_HealthDomainFatalErrorData: accessed-variable=pSR_HealthDomainFatalError.HealthDomainFatalErrorData
              DSP_pSR_HealthDomainHeartbeat_HealthDomainHeartbeatData: accessed-variable=pSR_HealthDomainHeartbeat.HealthDomainHeartbeatData
              DSP_pSR_HealthDumpData_HealthDumpDataData: accessed-variable=pSR_HealthDumpData.HealthDumpDataData
              DSP_pSR_HealthDumpHdrInfo_HealthDumpHdrInfoData: accessed-variable=pSR_HealthDumpHdrInfo.HealthDumpHdrInfoData
              DSP_pSR_HealthEventRecord_HealthEventRecordData: accessed-variable=pSR_HealthEventRecord.HealthEventRecordData
              DWA_pSR_HudWarningStatus_HudWarningStatusData: accessed-variable=pSR_HudWarningStatus.HudWarningStatusData
              DSP_pSR_PowerExtendShutdownTime_PowerExtendShutdownTimeData: accessed-variable=pSR_PowerExtendShutdownTime.PowerExtendShutdownTimeData
              DSP_pSR_PowerKeepSystemAwake_PowerKeepSystemAwakeData: accessed-variable=pSR_PowerKeepSystemAwake.PowerKeepSystemAwakeData
              DWA_pSR_PowerSystemState_PowerSystemStateData: accessed-variable=pSR_PowerSystemState.PowerSystemStateData
              DWA_pSR_WarningDisplayAvailable_WarningDisplayAvailableData: accessed-variable=pSR_WarningDisplayAvailable.WarningDisplayAvailableData
              DWA_pSR_WarningStatus_WarningStatusData: accessed-variable=pSR_WarningStatus.WarningStatusData
              DSP_pSR_MainHMIReadyStatus_MainHMIReadyStatusData: accessed-variable=pSR_MainHMIReadyStatus.MainHMIReadyStatusData
              DSP_pSR_SafeHMIReadyStatus_SafeHMIReadyStatusData: accessed-variable=pSR_SafeHMIReadyStatus.SafeHMIReadyStatusData
              DSP_pSR_DiagResponse_DiagResponseData: accessed-variable=pSR_DiagResponse.DiagResponseData
              DSP_pSR_UpdateShortServiceResp_UpdateShortServiceRespData: accessed-variable=pSR_UpdateShortServiceResp.UpdateShortServiceRespData
              DWA_pSR_DLTControlMessageRequest_DLTControlMessageRequestData: accessed-variable=pSR_DLTControlMessageRequest.DLTControlMessageRequestData
              DWA_pSR_DLTMessageReadAck_DLTMessageReadAckData: accessed-variable=pSR_DLTMessageReadAck.DLTMessageReadAckData
          sync call OA_rCS_UclSystemCallbacks_ErrorNotification: operation=rCS_UclSystemCallbacks.ErrorNotification
          sync call OA_rCS_UclSystemCallbacks_LinkStatusChanged: operation=rCS_UclSystemCallbacks.LinkStatusChanged
        OnDre_FastGaugeInfo
          data-receive-point-by-arguments:
            25 x access:
              DRP_rSR_DiagDIDRequest_DiagDIDRequestData: accessed-variable=rSR_DiagDIDRequest.DiagDIDRequestData
              DRP_rSR_DiagIOCtrlRequest_DiagIOCtrlRequestData: accessed-variable=rSR_DiagIOCtrlRequest.DiagIOCtrlRequestData
              DRP_rSR_DiagRoutineRequest_DiagRoutineRequestData: accessed-variable=rSR_DiagRoutineRequest.DiagRoutineRequestData
              DRA_rSR_DisplaySetPower_DisplaySetPowerData: accessed-variable=rSR_DisplaySetPower.DisplaySetPowerData
              DRA_rSR_FRTT_Status_FRTT_StatusData: accessed-variable=rSR_FRTT_Status.FRTT_StatusData
              DRA_rSR_FastGaugeInfo_FastGaugeInfoData: accessed-variable=rSR_FastGaugeInfo.FastGaugeInfoData
              DRP_rSR_HealthDumpGetData_HealthDumpGetDataData: accessed-variable=rSR_HealthDumpGetData.HealthDumpGetDataData
              DRP_rSR_HealthDumpGetHdr_HealthDumpGetHdrData: accessed-variable=rSR_HealthDumpGetHdr.HealthDumpGetHdrData
              DRA_rSR_HudWarningDisplay_HudWarningDisplayData: accessed-variable=rSR_HudWarningDisplay.HudWarningDisplayData
              DRP_rSR_IgnState_IgnStateData: accessed-variable=rSR_IgnState.IgnStateData
              DRA_rSR_IlluminationData_IlluminationDataData: accessed-variable=rSR_IlluminationData.IlluminationDataData
              DRA_rSR_PowerSystemStateReqChange_PowerSystemStateReqChangeData: accessed-variable=rSR_PowerSystemStateReqChange.PowerSystemStateReqChangeData
              DRA_rSR_RTT_Icon_RTT_IconData: accessed-variable=rSR_RTT_Icon.RTT_IconData
              DRA_rSR_RTT_Status_RTT_StatusData: accessed-variable=rSR_RTT_Status.RTT_StatusData
              DRA_rSR_RTT_Toggle_RTT_ToggleData: accessed-variable=rSR_RTT_Toggle.RTT_ToggleData
              DRA_rSR_ShiftPosIndStatus_ShiftPosIndStatusData: accessed-variable=rSR_ShiftPosIndStatus.ShiftPosIndStatusData
              DRA_rSR_SlowGaugeInfo_SlowGaugeInfoData: accessed-variable=rSR_SlowGaugeInfo.SlowGaugeInfoData
              DRA_rSR_TT_Status_TT_StatusData: accessed-variable=rSR_TT_Status.TT_StatusData
              DRA_rSR_TpmsWarningData_TpmsWarningDataData: accessed-variable=rSR_TpmsWarningData.TpmsWarningDataData
              DRA_rSR_WarningDisplay_WarningDisplayData: accessed-variable=rSR_WarningDisplay.WarningDisplayData
              DRA_rSR_WarningExtDisplay_WarningExtDisplayData: accessed-variable=rSR_WarningExtDisplay.WarningExtDisplayData
              DRP_rSR_UpdateLongServiceReq_UpdateLongServiceReqData: accessed-variable=rSR_UpdateLongServiceReq.UpdateLongServiceReqData
              DRP_rSR_UpdateShortServiceReq_UpdateShortServiceReqData: accessed-variable=rSR_UpdateShortServiceReq.UpdateShortServiceReqData
              DRA_rSR_DLTControlMessageReponse_DLTControlMessageReponseData: accessed-variable=rSR_DLTControlMessageReponse.DLTControlMessageReponseData
              DRA_rSR_DLTMessageReadRequest_DLTMessageReadRequestData: accessed-variable=rSR_DLTMessageReadRequest.DLTMessageReadRequestData
          data-send-points:
            19 x access:
              DWA_pSR_DisplayCurrentState_DisplayCurrentStateData: accessed-variable=pSR_DisplayCurrentState.DisplayCurrentStateData
              DWA_pSR_EmmcErrorNotifier_EmmcErrorNotifierData: accessed-variable=pSR_EmmcErrorNotifier.EmmcErrorNotifierData
              DSP_pSR_HealthDomainFatalError_HealthDomainFatalErrorData: accessed-variable=pSR_HealthDomainFatalError.HealthDomainFatalErrorData
              DSP_pSR_HealthDomainHeartbeat_HealthDomainHeartbeatData: accessed-variable=pSR_HealthDomainHeartbeat.HealthDomainHeartbeatData
              DSP_pSR_HealthDumpData_HealthDumpDataData: accessed-variable=pSR_HealthDumpData.HealthDumpDataData
              DSP_pSR_HealthDumpHdrInfo_HealthDumpHdrInfoData: accessed-variable=pSR_HealthDumpHdrInfo.HealthDumpHdrInfoData
              DSP_pSR_HealthEventRecord_HealthEventRecordData: accessed-variable=pSR_HealthEventRecord.HealthEventRecordData
              DWA_pSR_HudWarningStatus_HudWarningStatusData: accessed-variable=pSR_HudWarningStatus.HudWarningStatusData
              DSP_pSR_PowerExtendShutdownTime_PowerExtendShutdownTimeData: accessed-variable=pSR_PowerExtendShutdownTime.PowerExtendShutdownTimeData
              DSP_pSR_PowerKeepSystemAwake_PowerKeepSystemAwakeData: accessed-variable=pSR_PowerKeepSystemAwake.PowerKeepSystemAwakeData
              DWA_pSR_PowerSystemState_PowerSystemStateData: accessed-variable=pSR_PowerSystemState.PowerSystemStateData
              DWA_pSR_WarningDisplayAvailable_WarningDisplayAvailableData: accessed-variable=pSR_WarningDisplayAvailable.WarningDisplayAvailableData
              DWA_pSR_WarningStatus_WarningStatusData: accessed-variable=pSR_WarningStatus.WarningStatusData
              DSP_pSR_MainHMIReadyStatus_MainHMIReadyStatusData: accessed-variable=pSR_MainHMIReadyStatus.MainHMIReadyStatusData
              DSP_pSR_SafeHMIReadyStatus_SafeHMIReadyStatusData: accessed-variable=pSR_SafeHMIReadyStatus.SafeHMIReadyStatusData
              DSP_pSR_DiagResponse_DiagResponseData: accessed-variable=pSR_DiagResponse.DiagResponseData
              DSP_pSR_UpdateShortServiceResp_UpdateShortServiceRespData: accessed-variable=pSR_UpdateShortServiceResp.UpdateShortServiceRespData
              DWA_pSR_DLTControlMessageRequest_DLTControlMessageRequestData: accessed-variable=pSR_DLTControlMessageRequest.DLTControlMessageRequestData
              DWA_pSR_DLTMessageReadAck_DLTMessageReadAckData: accessed-variable=pSR_DLTMessageReadAck.DLTMessageReadAckData
          sync call OA_rCS_UclSystemCallbacks_ErrorNotification: operation=rCS_UclSystemCallbacks.ErrorNotification
          sync call OA_rCS_UclSystemCallbacks_LinkStatusChanged: operation=rCS_UclSystemCallbacks.LinkStatusChanged
        OnDre_IlluminationData
          data-receive-point-by-arguments:
            25 x access:
              DRP_rSR_DiagDIDRequest_DiagDIDRequestData: accessed-variable=rSR_DiagDIDRequest.DiagDIDRequestData
              DRP_rSR_DiagIOCtrlRequest_DiagIOCtrlRequestData: accessed-variable=rSR_DiagIOCtrlRequest.DiagIOCtrlRequestData
              DRP_rSR_DiagRoutineRequest_DiagRoutineRequestData: accessed-variable=rSR_DiagRoutineRequest.DiagRoutineRequestData
              DRA_rSR_DisplaySetPower_DisplaySetPowerData: accessed-variable=rSR_DisplaySetPower.DisplaySetPowerData
              DRA_rSR_FRTT_Status_FRTT_StatusData: accessed-variable=rSR_FRTT_Status.FRTT_StatusData
              DRA_rSR_FastGaugeInfo_FastGaugeInfoData: accessed-variable=rSR_FastGaugeInfo.FastGaugeInfoData
              DRP_rSR_HealthDumpGetData_HealthDumpGetDataData: accessed-variable=rSR_HealthDumpGetData.HealthDumpGetDataData
              DRP_rSR_HealthDumpGetHdr_HealthDumpGetHdrData: accessed-variable=rSR_HealthDumpGetHdr.HealthDumpGetHdrData
              DRA_rSR_HudWarningDisplay_HudWarningDisplayData: accessed-variable=rSR_HudWarningDisplay.HudWarningDisplayData
              DRP_rSR_IgnState_IgnStateData: accessed-variable=rSR_IgnState.IgnStateData
              DRA_rSR_IlluminationData_IlluminationDataData: accessed-variable=rSR_IlluminationData.IlluminationDataData
              DRA_rSR_PowerSystemStateReqChange_PowerSystemStateReqChangeData: accessed-variable=rSR_PowerSystemStateReqChange.PowerSystemStateReqChangeData
              DRA_rSR_RTT_Icon_RTT_IconData: accessed-variable=rSR_RTT_Icon.RTT_IconData
              DRA_rSR_RTT_Status_RTT_StatusData: accessed-variable=rSR_RTT_Status.RTT_StatusData
              DRA_rSR_RTT_Toggle_RTT_ToggleData: accessed-variable=rSR_RTT_Toggle.RTT_ToggleData
              DRA_rSR_ShiftPosIndStatus_ShiftPosIndStatusData: accessed-variable=rSR_ShiftPosIndStatus.ShiftPosIndStatusData
              DRA_rSR_SlowGaugeInfo_SlowGaugeInfoData: accessed-variable=rSR_SlowGaugeInfo.SlowGaugeInfoData
              DRA_rSR_TT_Status_TT_StatusData: accessed-variable=rSR_TT_Status.TT_StatusData
              DRA_rSR_TpmsWarningData_TpmsWarningDataData: accessed-variable=rSR_TpmsWarningData.TpmsWarningDataData
              DRA_rSR_WarningDisplay_WarningDisplayData: accessed-variable=rSR_WarningDisplay.WarningDisplayData
              DRA_rSR_WarningExtDisplay_WarningExtDisplayData: accessed-variable=rSR_WarningExtDisplay.WarningExtDisplayData
              DRP_rSR_UpdateLongServiceReq_UpdateLongServiceReqData: accessed-variable=rSR_UpdateLongServiceReq.UpdateLongServiceReqData
              DRP_rSR_UpdateShortServiceReq_UpdateShortServiceReqData: accessed-variable=rSR_UpdateShortServiceReq.UpdateShortServiceReqData
              DRA_rSR_DLTControlMessageReponse_DLTControlMessageReponseData: accessed-variable=rSR_DLTControlMessageReponse.DLTControlMessageReponseData
              DRA_rSR_DLTMessageReadRequest_DLTMessageReadRequestData: accessed-variable=rSR_DLTMessageReadRequest.DLTMessageReadRequestData
          data-send-points:
            19 x access:
              DWA_pSR_DisplayCurrentState_DisplayCurrentStateData: accessed-variable=pSR_DisplayCurrentState.DisplayCurrentStateData
              DWA_pSR_EmmcErrorNotifier_EmmcErrorNotifierData: accessed-variable=pSR_EmmcErrorNotifier.EmmcErrorNotifierData
              DSP_pSR_HealthDomainFatalError_HealthDomainFatalErrorData: accessed-variable=pSR_HealthDomainFatalError.HealthDomainFatalErrorData
              DSP_pSR_HealthDomainHeartbeat_HealthDomainHeartbeatData: accessed-variable=pSR_HealthDomainHeartbeat.HealthDomainHeartbeatData
              DSP_pSR_HealthDumpData_HealthDumpDataData: accessed-variable=pSR_HealthDumpData.HealthDumpDataData
              DSP_pSR_HealthDumpHdrInfo_HealthDumpHdrInfoData: accessed-variable=pSR_HealthDumpHdrInfo.HealthDumpHdrInfoData
              DSP_pSR_HealthEventRecord_HealthEventRecordData: accessed-variable=pSR_HealthEventRecord.HealthEventRecordData
              DWA_pSR_HudWarningStatus_HudWarningStatusData: accessed-variable=pSR_HudWarningStatus.HudWarningStatusData
              DSP_pSR_PowerExtendShutdownTime_PowerExtendShutdownTimeData: accessed-variable=pSR_PowerExtendShutdownTime.PowerExtendShutdownTimeData
              DSP_pSR_PowerKeepSystemAwake_PowerKeepSystemAwakeData: accessed-variable=pSR_PowerKeepSystemAwake.PowerKeepSystemAwakeData
              DWA_pSR_PowerSystemState_PowerSystemStateData: accessed-variable=pSR_PowerSystemState.PowerSystemStateData
              DWA_pSR_WarningDisplayAvailable_WarningDisplayAvailableData: accessed-variable=pSR_WarningDisplayAvailable.WarningDisplayAvailableData
              DWA_pSR_WarningStatus_WarningStatusData: accessed-variable=pSR_WarningStatus.WarningStatusData
              DSP_pSR_MainHMIReadyStatus_MainHMIReadyStatusData: accessed-variable=pSR_MainHMIReadyStatus.MainHMIReadyStatusData
              DSP_pSR_SafeHMIReadyStatus_SafeHMIReadyStatusData: accessed-variable=pSR_SafeHMIReadyStatus.SafeHMIReadyStatusData
              DSP_pSR_DiagResponse_DiagResponseData: accessed-variable=pSR_DiagResponse.DiagResponseData
              DSP_pSR_UpdateShortServiceResp_UpdateShortServiceRespData: accessed-variable=pSR_UpdateShortServiceResp.UpdateShortServiceRespData
              DWA_pSR_DLTControlMessageRequest_DLTControlMessageRequestData: accessed-variable=pSR_DLTControlMessageRequest.DLTControlMessageRequestData
              DWA_pSR_DLTMessageReadAck_DLTMessageReadAckData: accessed-variable=pSR_DLTMessageReadAck.DLTMessageReadAckData
          sync call OA_rCS_UclSystemCallbacks_ErrorNotification: operation=rCS_UclSystemCallbacks.ErrorNotification
          sync call OA_rCS_UclSystemCallbacks_LinkStatusChanged: operation=rCS_UclSystemCallbacks.LinkStatusChanged
        OnDre_RTT_Icon
          data-receive-point-by-arguments:
            25 x access:
              DRP_rSR_DiagDIDRequest_DiagDIDRequestData: accessed-variable=rSR_DiagDIDRequest.DiagDIDRequestData
              DRP_rSR_DiagIOCtrlRequest_DiagIOCtrlRequestData: accessed-variable=rSR_DiagIOCtrlRequest.DiagIOCtrlRequestData
              DRP_rSR_DiagRoutineRequest_DiagRoutineRequestData: accessed-variable=rSR_DiagRoutineRequest.DiagRoutineRequestData
              DRA_rSR_DisplaySetPower_DisplaySetPowerData: accessed-variable=rSR_DisplaySetPower.DisplaySetPowerData
              DRA_rSR_FRTT_Status_FRTT_StatusData: accessed-variable=rSR_FRTT_Status.FRTT_StatusData
              DRA_rSR_FastGaugeInfo_FastGaugeInfoData: accessed-variable=rSR_FastGaugeInfo.FastGaugeInfoData
              DRP_rSR_HealthDumpGetData_HealthDumpGetDataData: accessed-variable=rSR_HealthDumpGetData.HealthDumpGetDataData
              DRP_rSR_HealthDumpGetHdr_HealthDumpGetHdrData: accessed-variable=rSR_HealthDumpGetHdr.HealthDumpGetHdrData
              DRA_rSR_HudWarningDisplay_HudWarningDisplayData: accessed-variable=rSR_HudWarningDisplay.HudWarningDisplayData
              DRP_rSR_IgnState_IgnStateData: accessed-variable=rSR_IgnState.IgnStateData
              DRA_rSR_IlluminationData_IlluminationDataData: accessed-variable=rSR_IlluminationData.IlluminationDataData
              DRA_rSR_PowerSystemStateReqChange_PowerSystemStateReqChangeData: accessed-variable=rSR_PowerSystemStateReqChange.PowerSystemStateReqChangeData
              DRA_rSR_RTT_Icon_RTT_IconData: accessed-variable=rSR_RTT_Icon.RTT_IconData
              DRA_rSR_RTT_Status_RTT_StatusData: accessed-variable=rSR_RTT_Status.RTT_StatusData
              DRA_rSR_RTT_Toggle_RTT_ToggleData: accessed-variable=rSR_RTT_Toggle.RTT_ToggleData
              DRA_rSR_ShiftPosIndStatus_ShiftPosIndStatusData: accessed-variable=rSR_ShiftPosIndStatus.ShiftPosIndStatusData
              DRA_rSR_SlowGaugeInfo_SlowGaugeInfoData: accessed-variable=rSR_SlowGaugeInfo.SlowGaugeInfoData
              DRA_rSR_TT_Status_TT_StatusData: accessed-variable=rSR_TT_Status.TT_StatusData
              DRA_rSR_TpmsWarningData_TpmsWarningDataData: accessed-variable=rSR_TpmsWarningData.TpmsWarningDataData
              DRA_rSR_WarningDisplay_WarningDisplayData: accessed-variable=rSR_WarningDisplay.WarningDisplayData
              DRA_rSR_WarningExtDisplay_WarningExtDisplayData: accessed-variable=rSR_WarningExtDisplay.WarningExtDisplayData
              DRP_rSR_UpdateLongServiceReq_UpdateLongServiceReqData: accessed-variable=rSR_UpdateLongServiceReq.UpdateLongServiceReqData
              DRP_rSR_UpdateShortServiceReq_UpdateShortServiceReqData: accessed-variable=rSR_UpdateShortServiceReq.UpdateShortServiceReqData
              DRA_rSR_DLTControlMessageReponse_DLTControlMessageReponseData: accessed-variable=rSR_DLTControlMessageReponse.DLTControlMessageReponseData
              DRA_rSR_DLTMessageReadRequest_DLTMessageReadRequestData: accessed-variable=rSR_DLTMessageReadRequest.DLTMessageReadRequestData
          data-send-points:
            19 x access:
              DWA_pSR_DisplayCurrentState_DisplayCurrentStateData: accessed-variable=pSR_DisplayCurrentState.DisplayCurrentStateData
              DWA_pSR_EmmcErrorNotifier_EmmcErrorNotifierData: accessed-variable=pSR_EmmcErrorNotifier.EmmcErrorNotifierData
              DSP_pSR_HealthDomainFatalError_HealthDomainFatalErrorData: accessed-variable=pSR_HealthDomainFatalError.HealthDomainFatalErrorData
              DSP_pSR_HealthDomainHeartbeat_HealthDomainHeartbeatData: accessed-variable=pSR_HealthDomainHeartbeat.HealthDomainHeartbeatData
              DSP_pSR_HealthDumpData_HealthDumpDataData: accessed-variable=pSR_HealthDumpData.HealthDumpDataData
              DSP_pSR_HealthDumpHdrInfo_HealthDumpHdrInfoData: accessed-variable=pSR_HealthDumpHdrInfo.HealthDumpHdrInfoData
              DSP_pSR_HealthEventRecord_HealthEventRecordData: accessed-variable=pSR_HealthEventRecord.HealthEventRecordData
              DWA_pSR_HudWarningStatus_HudWarningStatusData: accessed-variable=pSR_HudWarningStatus.HudWarningStatusData
              DSP_pSR_PowerExtendShutdownTime_PowerExtendShutdownTimeData: accessed-variable=pSR_PowerExtendShutdownTime.PowerExtendShutdownTimeData
              DSP_pSR_PowerKeepSystemAwake_PowerKeepSystemAwakeData: accessed-variable=pSR_PowerKeepSystemAwake.PowerKeepSystemAwakeData
              DWA_pSR_PowerSystemState_PowerSystemStateData: accessed-variable=pSR_PowerSystemState.PowerSystemStateData
              DWA_pSR_WarningDisplayAvailable_WarningDisplayAvailableData: accessed-variable=pSR_WarningDisplayAvailable.WarningDisplayAvailableData
              DWA_pSR_WarningStatus_WarningStatusData: accessed-variable=pSR_WarningStatus.WarningStatusData
              DSP_pSR_MainHMIReadyStatus_MainHMIReadyStatusData: accessed-variable=pSR_MainHMIReadyStatus.MainHMIReadyStatusData
              DSP_pSR_SafeHMIReadyStatus_SafeHMIReadyStatusData: accessed-variable=pSR_SafeHMIReadyStatus.SafeHMIReadyStatusData
              DSP_pSR_DiagResponse_DiagResponseData: accessed-variable=pSR_DiagResponse.DiagResponseData
              DSP_pSR_UpdateShortServiceResp_UpdateShortServiceRespData: accessed-variable=pSR_UpdateShortServiceResp.UpdateShortServiceRespData
              DWA_pSR_DLTControlMessageRequest_DLTControlMessageRequestData: accessed-variable=pSR_DLTControlMessageRequest.DLTControlMessageRequestData
              DWA_pSR_DLTMessageReadAck_DLTMessageReadAckData: accessed-variable=pSR_DLTMessageReadAck.DLTMessageReadAckData
          sync call OA_rCS_UclSystemCallbacks_ErrorNotification: operation=rCS_UclSystemCallbacks.ErrorNotification
          sync call OA_rCS_UclSystemCallbacks_LinkStatusChanged: operation=rCS_UclSystemCallbacks.LinkStatusChanged
        OnDre_RTT_Status
          data-receive-point-by-arguments:
            25 x access:
              DRP_rSR_DiagDIDRequest_DiagDIDRequestData: accessed-variable=rSR_DiagDIDRequest.DiagDIDRequestData
              DRP_rSR_DiagIOCtrlRequest_DiagIOCtrlRequestData: accessed-variable=rSR_DiagIOCtrlRequest.DiagIOCtrlRequestData
              DRP_rSR_DiagRoutineRequest_DiagRoutineRequestData: accessed-variable=rSR_DiagRoutineRequest.DiagRoutineRequestData
              DRA_rSR_DisplaySetPower_DisplaySetPowerData: accessed-variable=rSR_DisplaySetPower.DisplaySetPowerData
              DRA_rSR_FRTT_Status_FRTT_StatusData: accessed-variable=rSR_FRTT_Status.FRTT_StatusData
              DRA_rSR_FastGaugeInfo_FastGaugeInfoData: accessed-variable=rSR_FastGaugeInfo.FastGaugeInfoData
              DRP_rSR_HealthDumpGetData_HealthDumpGetDataData: accessed-variable=rSR_HealthDumpGetData.HealthDumpGetDataData
              DRP_rSR_HealthDumpGetHdr_HealthDumpGetHdrData: accessed-variable=rSR_HealthDumpGetHdr.HealthDumpGetHdrData
              DRA_rSR_HudWarningDisplay_HudWarningDisplayData: accessed-variable=rSR_HudWarningDisplay.HudWarningDisplayData
              DRP_rSR_IgnState_IgnStateData: accessed-variable=rSR_IgnState.IgnStateData
              DRA_rSR_IlluminationData_IlluminationDataData: accessed-variable=rSR_IlluminationData.IlluminationDataData
              DRA_rSR_PowerSystemStateReqChange_PowerSystemStateReqChangeData: accessed-variable=rSR_PowerSystemStateReqChange.PowerSystemStateReqChangeData
              DRA_rSR_RTT_Icon_RTT_IconData: accessed-variable=rSR_RTT_Icon.RTT_IconData
              DRA_rSR_RTT_Status_RTT_StatusData: accessed-variable=rSR_RTT_Status.RTT_StatusData
              DRA_rSR_RTT_Toggle_RTT_ToggleData: accessed-variable=rSR_RTT_Toggle.RTT_ToggleData
              DRA_rSR_ShiftPosIndStatus_ShiftPosIndStatusData: accessed-variable=rSR_ShiftPosIndStatus.ShiftPosIndStatusData
              DRA_rSR_SlowGaugeInfo_SlowGaugeInfoData: accessed-variable=rSR_SlowGaugeInfo.SlowGaugeInfoData
              DRA_rSR_TT_Status_TT_StatusData: accessed-variable=rSR_TT_Status.TT_StatusData
              DRA_rSR_TpmsWarningData_TpmsWarningDataData: accessed-variable=rSR_TpmsWarningData.TpmsWarningDataData
              DRA_rSR_WarningDisplay_WarningDisplayData: accessed-variable=rSR_WarningDisplay.WarningDisplayData
              DRA_rSR_WarningExtDisplay_WarningExtDisplayData: accessed-variable=rSR_WarningExtDisplay.WarningExtDisplayData
              DRP_rSR_UpdateLongServiceReq_UpdateLongServiceReqData: accessed-variable=rSR_UpdateLongServiceReq.UpdateLongServiceReqData
              DRP_rSR_UpdateShortServiceReq_UpdateShortServiceReqData: accessed-variable=rSR_UpdateShortServiceReq.UpdateShortServiceReqData
              DRA_rSR_DLTControlMessageReponse_DLTControlMessageReponseData: accessed-variable=rSR_DLTControlMessageReponse.DLTControlMessageReponseData
              DRA_rSR_DLTMessageReadRequest_DLTMessageReadRequestData: accessed-variable=rSR_DLTMessageReadRequest.DLTMessageReadRequestData
          data-send-points:
            19 x access:
              DWA_pSR_DisplayCurrentState_DisplayCurrentStateData: accessed-variable=pSR_DisplayCurrentState.DisplayCurrentStateData
              DWA_pSR_EmmcErrorNotifier_EmmcErrorNotifierData: accessed-variable=pSR_EmmcErrorNotifier.EmmcErrorNotifierData
              DSP_pSR_HealthDomainFatalError_HealthDomainFatalErrorData: accessed-variable=pSR_HealthDomainFatalError.HealthDomainFatalErrorData
              DSP_pSR_HealthDomainHeartbeat_HealthDomainHeartbeatData: accessed-variable=pSR_HealthDomainHeartbeat.HealthDomainHeartbeatData
              DSP_pSR_HealthDumpData_HealthDumpDataData: accessed-variable=pSR_HealthDumpData.HealthDumpDataData
              DSP_pSR_HealthDumpHdrInfo_HealthDumpHdrInfoData: accessed-variable=pSR_HealthDumpHdrInfo.HealthDumpHdrInfoData
              DSP_pSR_HealthEventRecord_HealthEventRecordData: accessed-variable=pSR_HealthEventRecord.HealthEventRecordData
              DWA_pSR_HudWarningStatus_HudWarningStatusData: accessed-variable=pSR_HudWarningStatus.HudWarningStatusData
              DSP_pSR_PowerExtendShutdownTime_PowerExtendShutdownTimeData: accessed-variable=pSR_PowerExtendShutdownTime.PowerExtendShutdownTimeData
              DSP_pSR_PowerKeepSystemAwake_PowerKeepSystemAwakeData: accessed-variable=pSR_PowerKeepSystemAwake.PowerKeepSystemAwakeData
              DWA_pSR_PowerSystemState_PowerSystemStateData: accessed-variable=pSR_PowerSystemState.PowerSystemStateData
              DWA_pSR_WarningDisplayAvailable_WarningDisplayAvailableData: accessed-variable=pSR_WarningDisplayAvailable.WarningDisplayAvailableData
              DWA_pSR_WarningStatus_WarningStatusData: accessed-variable=pSR_WarningStatus.WarningStatusData
              DSP_pSR_MainHMIReadyStatus_MainHMIReadyStatusData: accessed-variable=pSR_MainHMIReadyStatus.MainHMIReadyStatusData
              DSP_pSR_SafeHMIReadyStatus_SafeHMIReadyStatusData: accessed-variable=pSR_SafeHMIReadyStatus.SafeHMIReadyStatusData
              DSP_pSR_DiagResponse_DiagResponseData: accessed-variable=pSR_DiagResponse.DiagResponseData
              DSP_pSR_UpdateShortServiceResp_UpdateShortServiceRespData: accessed-variable=pSR_UpdateShortServiceResp.UpdateShortServiceRespData
              DWA_pSR_DLTControlMessageRequest_DLTControlMessageRequestData: accessed-variable=pSR_DLTControlMessageRequest.DLTControlMessageRequestData
              DWA_pSR_DLTMessageReadAck_DLTMessageReadAckData: accessed-variable=pSR_DLTMessageReadAck.DLTMessageReadAckData
          sync call OA_rCS_UclSystemCallbacks_ErrorNotification: operation=rCS_UclSystemCallbacks.ErrorNotification
          sync call OA_rCS_UclSystemCallbacks_LinkStatusChanged: operation=rCS_UclSystemCallbacks.LinkStatusChanged
        OnDre_RTT_Toggle
          data-receive-point-by-arguments:
            25 x access:
              DRP_rSR_DiagDIDRequest_DiagDIDRequestData: accessed-variable=rSR_DiagDIDRequest.DiagDIDRequestData
              DRP_rSR_DiagIOCtrlRequest_DiagIOCtrlRequestData: accessed-variable=rSR_DiagIOCtrlRequest.DiagIOCtrlRequestData
              DRP_rSR_DiagRoutineRequest_DiagRoutineRequestData: accessed-variable=rSR_DiagRoutineRequest.DiagRoutineRequestData
              DRA_rSR_DisplaySetPower_DisplaySetPowerData: accessed-variable=rSR_DisplaySetPower.DisplaySetPowerData
              DRA_rSR_FRTT_Status_FRTT_StatusData: accessed-variable=rSR_FRTT_Status.FRTT_StatusData
              DRA_rSR_FastGaugeInfo_FastGaugeInfoData: accessed-variable=rSR_FastGaugeInfo.FastGaugeInfoData
              DRP_rSR_HealthDumpGetData_HealthDumpGetDataData: accessed-variable=rSR_HealthDumpGetData.HealthDumpGetDataData
              DRP_rSR_HealthDumpGetHdr_HealthDumpGetHdrData: accessed-variable=rSR_HealthDumpGetHdr.HealthDumpGetHdrData
              DRA_rSR_HudWarningDisplay_HudWarningDisplayData: accessed-variable=rSR_HudWarningDisplay.HudWarningDisplayData
              DRP_rSR_IgnState_IgnStateData: accessed-variable=rSR_IgnState.IgnStateData
              DRA_rSR_IlluminationData_IlluminationDataData: accessed-variable=rSR_IlluminationData.IlluminationDataData
              DRA_rSR_PowerSystemStateReqChange_PowerSystemStateReqChangeData: accessed-variable=rSR_PowerSystemStateReqChange.PowerSystemStateReqChangeData
              DRA_rSR_RTT_Icon_RTT_IconData: accessed-variable=rSR_RTT_Icon.RTT_IconData
              DRA_rSR_RTT_Status_RTT_StatusData: accessed-variable=rSR_RTT_Status.RTT_StatusData
              DRA_rSR_RTT_Toggle_RTT_ToggleData: accessed-variable=rSR_RTT_Toggle.RTT_ToggleData
              DRA_rSR_ShiftPosIndStatus_ShiftPosIndStatusData: accessed-variable=rSR_ShiftPosIndStatus.ShiftPosIndStatusData
              DRA_rSR_SlowGaugeInfo_SlowGaugeInfoData: accessed-variable=rSR_SlowGaugeInfo.SlowGaugeInfoData
              DRA_rSR_TT_Status_TT_StatusData: accessed-variable=rSR_TT_Status.TT_StatusData
              DRA_rSR_TpmsWarningData_TpmsWarningDataData: accessed-variable=rSR_TpmsWarningData.TpmsWarningDataData
              DRA_rSR_WarningDisplay_WarningDisplayData: accessed-variable=rSR_WarningDisplay.WarningDisplayData
              DRA_rSR_WarningExtDisplay_WarningExtDisplayData: accessed-variable=rSR_WarningExtDisplay.WarningExtDisplayData
              DRP_rSR_UpdateLongServiceReq_UpdateLongServiceReqData: accessed-variable=rSR_UpdateLongServiceReq.UpdateLongServiceReqData
              DRP_rSR_UpdateShortServiceReq_UpdateShortServiceReqData: accessed-variable=rSR_UpdateShortServiceReq.UpdateShortServiceReqData
              DRA_rSR_DLTControlMessageReponse_DLTControlMessageReponseData: accessed-variable=rSR_DLTControlMessageReponse.DLTControlMessageReponseData
              DRA_rSR_DLTMessageReadRequest_DLTMessageReadRequestData: accessed-variable=rSR_DLTMessageReadRequest.DLTMessageReadRequestData
          data-send-points:
            19 x access:
              DWA_pSR_DisplayCurrentState_DisplayCurrentStateData: accessed-variable=pSR_DisplayCurrentState.DisplayCurrentStateData
              DWA_pSR_EmmcErrorNotifier_EmmcErrorNotifierData: accessed-variable=pSR_EmmcErrorNotifier.EmmcErrorNotifierData
              DSP_pSR_HealthDomainFatalError_HealthDomainFatalErrorData: accessed-variable=pSR_HealthDomainFatalError.HealthDomainFatalErrorData
              DSP_pSR_HealthDomainHeartbeat_HealthDomainHeartbeatData: accessed-variable=pSR_HealthDomainHeartbeat.HealthDomainHeartbeatData
              DSP_pSR_HealthDumpData_HealthDumpDataData: accessed-variable=pSR_HealthDumpData.HealthDumpDataData
              DSP_pSR_HealthDumpHdrInfo_HealthDumpHdrInfoData: accessed-variable=pSR_HealthDumpHdrInfo.HealthDumpHdrInfoData
              DSP_pSR_HealthEventRecord_HealthEventRecordData: accessed-variable=pSR_HealthEventRecord.HealthEventRecordData
              DWA_pSR_HudWarningStatus_HudWarningStatusData: accessed-variable=pSR_HudWarningStatus.HudWarningStatusData
              DSP_pSR_PowerExtendShutdownTime_PowerExtendShutdownTimeData: accessed-variable=pSR_PowerExtendShutdownTime.PowerExtendShutdownTimeData
              DSP_pSR_PowerKeepSystemAwake_PowerKeepSystemAwakeData: accessed-variable=pSR_PowerKeepSystemAwake.PowerKeepSystemAwakeData
              DWA_pSR_PowerSystemState_PowerSystemStateData: accessed-variable=pSR_PowerSystemState.PowerSystemStateData
              DWA_pSR_WarningDisplayAvailable_WarningDisplayAvailableData: accessed-variable=pSR_WarningDisplayAvailable.WarningDisplayAvailableData
              DWA_pSR_WarningStatus_WarningStatusData: accessed-variable=pSR_WarningStatus.WarningStatusData
              DSP_pSR_MainHMIReadyStatus_MainHMIReadyStatusData: accessed-variable=pSR_MainHMIReadyStatus.MainHMIReadyStatusData
              DSP_pSR_SafeHMIReadyStatus_SafeHMIReadyStatusData: accessed-variable=pSR_SafeHMIReadyStatus.SafeHMIReadyStatusData
              DSP_pSR_DiagResponse_DiagResponseData: accessed-variable=pSR_DiagResponse.DiagResponseData
              DSP_pSR_UpdateShortServiceResp_UpdateShortServiceRespData: accessed-variable=pSR_UpdateShortServiceResp.UpdateShortServiceRespData
              DWA_pSR_DLTControlMessageRequest_DLTControlMessageRequestData: accessed-variable=pSR_DLTControlMessageRequest.DLTControlMessageRequestData
              DWA_pSR_DLTMessageReadAck_DLTMessageReadAckData: accessed-variable=pSR_DLTMessageReadAck.DLTMessageReadAckData
          sync call OA_rCS_UclSystemCallbacks_ErrorNotification: operation=rCS_UclSystemCallbacks.ErrorNotification
          sync call OA_rCS_UclSystemCallbacks_LinkStatusChanged: operation=rCS_UclSystemCallbacks.LinkStatusChanged
        OnDre_ShiftPosIndStatus
          data-receive-point-by-arguments:
            25 x access:
              DRP_rSR_DiagDIDRequest_DiagDIDRequestData: accessed-variable=rSR_DiagDIDRequest.DiagDIDRequestData
              DRP_rSR_DiagIOCtrlRequest_DiagIOCtrlRequestData: accessed-variable=rSR_DiagIOCtrlRequest.DiagIOCtrlRequestData
              DRP_rSR_DiagRoutineRequest_DiagRoutineRequestData: accessed-variable=rSR_DiagRoutineRequest.DiagRoutineRequestData
              DRA_rSR_DisplaySetPower_DisplaySetPowerData: accessed-variable=rSR_DisplaySetPower.DisplaySetPowerData
              DRA_rSR_FRTT_Status_FRTT_StatusData: accessed-variable=rSR_FRTT_Status.FRTT_StatusData
              DRA_rSR_FastGaugeInfo_FastGaugeInfoData: accessed-variable=rSR_FastGaugeInfo.FastGaugeInfoData
              DRP_rSR_HealthDumpGetData_HealthDumpGetDataData: accessed-variable=rSR_HealthDumpGetData.HealthDumpGetDataData
              DRP_rSR_HealthDumpGetHdr_HealthDumpGetHdrData: accessed-variable=rSR_HealthDumpGetHdr.HealthDumpGetHdrData
              DRA_rSR_HudWarningDisplay_HudWarningDisplayData: accessed-variable=rSR_HudWarningDisplay.HudWarningDisplayData
              DRP_rSR_IgnState_IgnStateData: accessed-variable=rSR_IgnState.IgnStateData
              DRA_rSR_IlluminationData_IlluminationDataData: accessed-variable=rSR_IlluminationData.IlluminationDataData
              DRA_rSR_PowerSystemStateReqChange_PowerSystemStateReqChangeData: accessed-variable=rSR_PowerSystemStateReqChange.PowerSystemStateReqChangeData
              DRA_rSR_RTT_Icon_RTT_IconData: accessed-variable=rSR_RTT_Icon.RTT_IconData
              DRA_rSR_RTT_Status_RTT_StatusData: accessed-variable=rSR_RTT_Status.RTT_StatusData
              DRA_rSR_RTT_Toggle_RTT_ToggleData: accessed-variable=rSR_RTT_Toggle.RTT_ToggleData
              DRA_rSR_ShiftPosIndStatus_ShiftPosIndStatusData: accessed-variable=rSR_ShiftPosIndStatus.ShiftPosIndStatusData
              DRA_rSR_SlowGaugeInfo_SlowGaugeInfoData: accessed-variable=rSR_SlowGaugeInfo.SlowGaugeInfoData
              DRA_rSR_TT_Status_TT_StatusData: accessed-variable=rSR_TT_Status.TT_StatusData
              DRA_rSR_TpmsWarningData_TpmsWarningDataData: accessed-variable=rSR_TpmsWarningData.TpmsWarningDataData
              DRA_rSR_WarningDisplay_WarningDisplayData: accessed-variable=rSR_WarningDisplay.WarningDisplayData
              DRA_rSR_WarningExtDisplay_WarningExtDisplayData: accessed-variable=rSR_WarningExtDisplay.WarningExtDisplayData
              DRP_rSR_UpdateLongServiceReq_UpdateLongServiceReqData: accessed-variable=rSR_UpdateLongServiceReq.UpdateLongServiceReqData
              DRP_rSR_UpdateShortServiceReq_UpdateShortServiceReqData: accessed-variable=rSR_UpdateShortServiceReq.UpdateShortServiceReqData
              DRA_rSR_DLTControlMessageReponse_DLTControlMessageReponseData: accessed-variable=rSR_DLTControlMessageReponse.DLTControlMessageReponseData
              DRA_rSR_DLTMessageReadRequest_DLTMessageReadRequestData: accessed-variable=rSR_DLTMessageReadRequest.DLTMessageReadRequestData
          data-send-points:
            19 x access:
              DWA_pSR_DisplayCurrentState_DisplayCurrentStateData: accessed-variable=pSR_DisplayCurrentState.DisplayCurrentStateData
              DWA_pSR_EmmcErrorNotifier_EmmcErrorNotifierData: accessed-variable=pSR_EmmcErrorNotifier.EmmcErrorNotifierData
              DSP_pSR_HealthDomainFatalError_HealthDomainFatalErrorData: accessed-variable=pSR_HealthDomainFatalError.HealthDomainFatalErrorData
              DSP_pSR_HealthDomainHeartbeat_HealthDomainHeartbeatData: accessed-variable=pSR_HealthDomainHeartbeat.HealthDomainHeartbeatData
              DSP_pSR_HealthDumpData_HealthDumpDataData: accessed-variable=pSR_HealthDumpData.HealthDumpDataData
              DSP_pSR_HealthDumpHdrInfo_HealthDumpHdrInfoData: accessed-variable=pSR_HealthDumpHdrInfo.HealthDumpHdrInfoData
              DSP_pSR_HealthEventRecord_HealthEventRecordData: accessed-variable=pSR_HealthEventRecord.HealthEventRecordData
              DWA_pSR_HudWarningStatus_HudWarningStatusData: accessed-variable=pSR_HudWarningStatus.HudWarningStatusData
              DSP_pSR_PowerExtendShutdownTime_PowerExtendShutdownTimeData: accessed-variable=pSR_PowerExtendShutdownTime.PowerExtendShutdownTimeData
              DSP_pSR_PowerKeepSystemAwake_PowerKeepSystemAwakeData: accessed-variable=pSR_PowerKeepSystemAwake.PowerKeepSystemAwakeData
              DWA_pSR_PowerSystemState_PowerSystemStateData: accessed-variable=pSR_PowerSystemState.PowerSystemStateData
              DWA_pSR_WarningDisplayAvailable_WarningDisplayAvailableData: accessed-variable=pSR_WarningDisplayAvailable.WarningDisplayAvailableData
              DWA_pSR_WarningStatus_WarningStatusData: accessed-variable=pSR_WarningStatus.WarningStatusData
              DSP_pSR_MainHMIReadyStatus_MainHMIReadyStatusData: accessed-variable=pSR_MainHMIReadyStatus.MainHMIReadyStatusData
              DSP_pSR_SafeHMIReadyStatus_SafeHMIReadyStatusData: accessed-variable=pSR_SafeHMIReadyStatus.SafeHMIReadyStatusData
              DSP_pSR_DiagResponse_DiagResponseData: accessed-variable=pSR_DiagResponse.DiagResponseData
              DSP_pSR_UpdateShortServiceResp_UpdateShortServiceRespData: accessed-variable=pSR_UpdateShortServiceResp.UpdateShortServiceRespData
              DWA_pSR_DLTControlMessageRequest_DLTControlMessageRequestData: accessed-variable=pSR_DLTControlMessageRequest.DLTControlMessageRequestData
              DWA_pSR_DLTMessageReadAck_DLTMessageReadAckData: accessed-variable=pSR_DLTMessageReadAck.DLTMessageReadAckData
          sync call OA_rCS_UclSystemCallbacks_ErrorNotification: operation=rCS_UclSystemCallbacks.ErrorNotification
          sync call OA_rCS_UclSystemCallbacks_LinkStatusChanged: operation=rCS_UclSystemCallbacks.LinkStatusChanged
        OnDre_SlowGaugeInfo
          data-receive-point-by-arguments:
            25 x access:
              DRP_rSR_DiagDIDRequest_DiagDIDRequestData: accessed-variable=rSR_DiagDIDRequest.DiagDIDRequestData
              DRP_rSR_DiagIOCtrlRequest_DiagIOCtrlRequestData: accessed-variable=rSR_DiagIOCtrlRequest.DiagIOCtrlRequestData
              DRP_rSR_DiagRoutineRequest_DiagRoutineRequestData: accessed-variable=rSR_DiagRoutineRequest.DiagRoutineRequestData
              DRA_rSR_DisplaySetPower_DisplaySetPowerData: accessed-variable=rSR_DisplaySetPower.DisplaySetPowerData
              DRA_rSR_FRTT_Status_FRTT_StatusData: accessed-variable=rSR_FRTT_Status.FRTT_StatusData
              DRA_rSR_FastGaugeInfo_FastGaugeInfoData: accessed-variable=rSR_FastGaugeInfo.FastGaugeInfoData
              DRP_rSR_HealthDumpGetData_HealthDumpGetDataData: accessed-variable=rSR_HealthDumpGetData.HealthDumpGetDataData
              DRP_rSR_HealthDumpGetHdr_HealthDumpGetHdrData: accessed-variable=rSR_HealthDumpGetHdr.HealthDumpGetHdrData
              DRA_rSR_HudWarningDisplay_HudWarningDisplayData: accessed-variable=rSR_HudWarningDisplay.HudWarningDisplayData
              DRP_rSR_IgnState_IgnStateData: accessed-variable=rSR_IgnState.IgnStateData
              DRA_rSR_IlluminationData_IlluminationDataData: accessed-variable=rSR_IlluminationData.IlluminationDataData
              DRA_rSR_PowerSystemStateReqChange_PowerSystemStateReqChangeData: accessed-variable=rSR_PowerSystemStateReqChange.PowerSystemStateReqChangeData
              DRA_rSR_RTT_Icon_RTT_IconData: accessed-variable=rSR_RTT_Icon.RTT_IconData
              DRA_rSR_RTT_Status_RTT_StatusData: accessed-variable=rSR_RTT_Status.RTT_StatusData
              DRA_rSR_RTT_Toggle_RTT_ToggleData: accessed-variable=rSR_RTT_Toggle.RTT_ToggleData
              DRA_rSR_ShiftPosIndStatus_ShiftPosIndStatusData: accessed-variable=rSR_ShiftPosIndStatus.ShiftPosIndStatusData
              DRA_rSR_SlowGaugeInfo_SlowGaugeInfoData: accessed-variable=rSR_SlowGaugeInfo.SlowGaugeInfoData
              DRA_rSR_TT_Status_TT_StatusData: accessed-variable=rSR_TT_Status.TT_StatusData
              DRA_rSR_TpmsWarningData_TpmsWarningDataData: accessed-variable=rSR_TpmsWarningData.TpmsWarningDataData
              DRA_rSR_WarningDisplay_WarningDisplayData: accessed-variable=rSR_WarningDisplay.WarningDisplayData
              DRA_rSR_WarningExtDisplay_WarningExtDisplayData: accessed-variable=rSR_WarningExtDisplay.WarningExtDisplayData
              DRP_rSR_UpdateLongServiceReq_UpdateLongServiceReqData: accessed-variable=rSR_UpdateLongServiceReq.UpdateLongServiceReqData
              DRP_rSR_UpdateShortServiceReq_UpdateShortServiceReqData: accessed-variable=rSR_UpdateShortServiceReq.UpdateShortServiceReqData
              DRA_rSR_DLTControlMessageReponse_DLTControlMessageReponseData: accessed-variable=rSR_DLTControlMessageReponse.DLTControlMessageReponseData
              DRA_rSR_DLTMessageReadRequest_DLTMessageReadRequestData: accessed-variable=rSR_DLTMessageReadRequest.DLTMessageReadRequestData
          data-send-points:
            19 x access:
              DWA_pSR_DisplayCurrentState_DisplayCurrentStateData: accessed-variable=pSR_DisplayCurrentState.DisplayCurrentStateData
              DWA_pSR_EmmcErrorNotifier_EmmcErrorNotifierData: accessed-variable=pSR_EmmcErrorNotifier.EmmcErrorNotifierData
              DSP_pSR_HealthDomainFatalError_HealthDomainFatalErrorData: accessed-variable=pSR_HealthDomainFatalError.HealthDomainFatalErrorData
              DSP_pSR_HealthDomainHeartbeat_HealthDomainHeartbeatData: accessed-variable=pSR_HealthDomainHeartbeat.HealthDomainHeartbeatData
              DSP_pSR_HealthDumpData_HealthDumpDataData: accessed-variable=pSR_HealthDumpData.HealthDumpDataData
              DSP_pSR_HealthDumpHdrInfo_HealthDumpHdrInfoData: accessed-variable=pSR_HealthDumpHdrInfo.HealthDumpHdrInfoData
              DSP_pSR_HealthEventRecord_HealthEventRecordData: accessed-variable=pSR_HealthEventRecord.HealthEventRecordData
              DWA_pSR_HudWarningStatus_HudWarningStatusData: accessed-variable=pSR_HudWarningStatus.HudWarningStatusData
              DSP_pSR_PowerExtendShutdownTime_PowerExtendShutdownTimeData: accessed-variable=pSR_PowerExtendShutdownTime.PowerExtendShutdownTimeData
              DSP_pSR_PowerKeepSystemAwake_PowerKeepSystemAwakeData: accessed-variable=pSR_PowerKeepSystemAwake.PowerKeepSystemAwakeData
              DWA_pSR_PowerSystemState_PowerSystemStateData: accessed-variable=pSR_PowerSystemState.PowerSystemStateData
              DWA_pSR_WarningDisplayAvailable_WarningDisplayAvailableData: accessed-variable=pSR_WarningDisplayAvailable.WarningDisplayAvailableData
              DWA_pSR_WarningStatus_WarningStatusData: accessed-variable=pSR_WarningStatus.WarningStatusData
              DSP_pSR_MainHMIReadyStatus_MainHMIReadyStatusData: accessed-variable=pSR_MainHMIReadyStatus.MainHMIReadyStatusData
              DSP_pSR_SafeHMIReadyStatus_SafeHMIReadyStatusData: accessed-variable=pSR_SafeHMIReadyStatus.SafeHMIReadyStatusData
              DSP_pSR_DiagResponse_DiagResponseData: accessed-variable=pSR_DiagResponse.DiagResponseData
              DSP_pSR_UpdateShortServiceResp_UpdateShortServiceRespData: accessed-variable=pSR_UpdateShortServiceResp.UpdateShortServiceRespData
              DWA_pSR_DLTControlMessageRequest_DLTControlMessageRequestData: accessed-variable=pSR_DLTControlMessageRequest.DLTControlMessageRequestData
              DWA_pSR_DLTMessageReadAck_DLTMessageReadAckData: accessed-variable=pSR_DLTMessageReadAck.DLTMessageReadAckData
          sync call OA_rCS_UclSystemCallbacks_ErrorNotification: operation=rCS_UclSystemCallbacks.ErrorNotification
          sync call OA_rCS_UclSystemCallbacks_LinkStatusChanged: operation=rCS_UclSystemCallbacks.LinkStatusChanged
        OnDre_TT_Status
          data-receive-point-by-arguments:
            25 x access:
              DRP_rSR_DiagDIDRequest_DiagDIDRequestData: accessed-variable=rSR_DiagDIDRequest.DiagDIDRequestData
              DRP_rSR_DiagIOCtrlRequest_DiagIOCtrlRequestData: accessed-variable=rSR_DiagIOCtrlRequest.DiagIOCtrlRequestData
              DRP_rSR_DiagRoutineRequest_DiagRoutineRequestData: accessed-variable=rSR_DiagRoutineRequest.DiagRoutineRequestData
              DRA_rSR_DisplaySetPower_DisplaySetPowerData: accessed-variable=rSR_DisplaySetPower.DisplaySetPowerData
              DRA_rSR_FRTT_Status_FRTT_StatusData: accessed-variable=rSR_FRTT_Status.FRTT_StatusData
              DRA_rSR_FastGaugeInfo_FastGaugeInfoData: accessed-variable=rSR_FastGaugeInfo.FastGaugeInfoData
              DRP_rSR_HealthDumpGetData_HealthDumpGetDataData: accessed-variable=rSR_HealthDumpGetData.HealthDumpGetDataData
              DRP_rSR_HealthDumpGetHdr_HealthDumpGetHdrData: accessed-variable=rSR_HealthDumpGetHdr.HealthDumpGetHdrData
              DRA_rSR_HudWarningDisplay_HudWarningDisplayData: accessed-variable=rSR_HudWarningDisplay.HudWarningDisplayData
              DRP_rSR_IgnState_IgnStateData: accessed-variable=rSR_IgnState.IgnStateData
              DRA_rSR_IlluminationData_IlluminationDataData: accessed-variable=rSR_IlluminationData.IlluminationDataData
              DRA_rSR_PowerSystemStateReqChange_PowerSystemStateReqChangeData: accessed-variable=rSR_PowerSystemStateReqChange.PowerSystemStateReqChangeData
              DRA_rSR_RTT_Icon_RTT_IconData: accessed-variable=rSR_RTT_Icon.RTT_IconData
              DRA_rSR_RTT_Status_RTT_StatusData: accessed-variable=rSR_RTT_Status.RTT_StatusData
              DRA_rSR_RTT_Toggle_RTT_ToggleData: accessed-variable=rSR_RTT_Toggle.RTT_ToggleData
              DRA_rSR_ShiftPosIndStatus_ShiftPosIndStatusData: accessed-variable=rSR_ShiftPosIndStatus.ShiftPosIndStatusData
              DRA_rSR_SlowGaugeInfo_SlowGaugeInfoData: accessed-variable=rSR_SlowGaugeInfo.SlowGaugeInfoData
              DRA_rSR_TT_Status_TT_StatusData: accessed-variable=rSR_TT_Status.TT_StatusData
              DRA_rSR_TpmsWarningData_TpmsWarningDataData: accessed-variable=rSR_TpmsWarningData.TpmsWarningDataData
              DRA_rSR_WarningDisplay_WarningDisplayData: accessed-variable=rSR_WarningDisplay.WarningDisplayData
              DRA_rSR_WarningExtDisplay_WarningExtDisplayData: accessed-variable=rSR_WarningExtDisplay.WarningExtDisplayData
              DRP_rSR_UpdateLongServiceReq_UpdateLongServiceReqData: accessed-variable=rSR_UpdateLongServiceReq.UpdateLongServiceReqData
              DRP_rSR_UpdateShortServiceReq_UpdateShortServiceReqData: accessed-variable=rSR_UpdateShortServiceReq.UpdateShortServiceReqData
              DRA_rSR_DLTControlMessageReponse_DLTControlMessageReponseData: accessed-variable=rSR_DLTControlMessageReponse.DLTControlMessageReponseData
              DRA_rSR_DLTMessageReadRequest_DLTMessageReadRequestData: accessed-variable=rSR_DLTMessageReadRequest.DLTMessageReadRequestData
          data-send-points:
            19 x access:
              DWA_pSR_DisplayCurrentState_DisplayCurrentStateData: accessed-variable=pSR_DisplayCurrentState.DisplayCurrentStateData
              DWA_pSR_EmmcErrorNotifier_EmmcErrorNotifierData: accessed-variable=pSR_EmmcErrorNotifier.EmmcErrorNotifierData
              DSP_pSR_HealthDomainFatalError_HealthDomainFatalErrorData: accessed-variable=pSR_HealthDomainFatalError.HealthDomainFatalErrorData
              DSP_pSR_HealthDomainHeartbeat_HealthDomainHeartbeatData: accessed-variable=pSR_HealthDomainHeartbeat.HealthDomainHeartbeatData
              DSP_pSR_HealthDumpData_HealthDumpDataData: accessed-variable=pSR_HealthDumpData.HealthDumpDataData
              DSP_pSR_HealthDumpHdrInfo_HealthDumpHdrInfoData: accessed-variable=pSR_HealthDumpHdrInfo.HealthDumpHdrInfoData
              DSP_pSR_HealthEventRecord_HealthEventRecordData: accessed-variable=pSR_HealthEventRecord.HealthEventRecordData
              DWA_pSR_HudWarningStatus_HudWarningStatusData: accessed-variable=pSR_HudWarningStatus.HudWarningStatusData
              DSP_pSR_PowerExtendShutdownTime_PowerExtendShutdownTimeData: accessed-variable=pSR_PowerExtendShutdownTime.PowerExtendShutdownTimeData
              DSP_pSR_PowerKeepSystemAwake_PowerKeepSystemAwakeData: accessed-variable=pSR_PowerKeepSystemAwake.PowerKeepSystemAwakeData
              DWA_pSR_PowerSystemState_PowerSystemStateData: accessed-variable=pSR_PowerSystemState.PowerSystemStateData
              DWA_pSR_WarningDisplayAvailable_WarningDisplayAvailableData: accessed-variable=pSR_WarningDisplayAvailable.WarningDisplayAvailableData
              DWA_pSR_WarningStatus_WarningStatusData: accessed-variable=pSR_WarningStatus.WarningStatusData
              DSP_pSR_MainHMIReadyStatus_MainHMIReadyStatusData: accessed-variable=pSR_MainHMIReadyStatus.MainHMIReadyStatusData
              DSP_pSR_SafeHMIReadyStatus_SafeHMIReadyStatusData: accessed-variable=pSR_SafeHMIReadyStatus.SafeHMIReadyStatusData
              DSP_pSR_DiagResponse_DiagResponseData: accessed-variable=pSR_DiagResponse.DiagResponseData
              DSP_pSR_UpdateShortServiceResp_UpdateShortServiceRespData: accessed-variable=pSR_UpdateShortServiceResp.UpdateShortServiceRespData
              DWA_pSR_DLTControlMessageRequest_DLTControlMessageRequestData: accessed-variable=pSR_DLTControlMessageRequest.DLTControlMessageRequestData
              DWA_pSR_DLTMessageReadAck_DLTMessageReadAckData: accessed-variable=pSR_DLTMessageReadAck.DLTMessageReadAckData
          sync call OA_rCS_UclSystemCallbacks_ErrorNotification: operation=rCS_UclSystemCallbacks.ErrorNotification
          sync call OA_rCS_UclSystemCallbacks_LinkStatusChanged: operation=rCS_UclSystemCallbacks.LinkStatusChanged
        OnDre_UpdateLongServiceReq
          data-receive-point-by-arguments:
            25 x access:
              DRP_rSR_DiagDIDRequest_DiagDIDRequestData: accessed-variable=rSR_DiagDIDRequest.DiagDIDRequestData
              DRP_rSR_DiagIOCtrlRequest_DiagIOCtrlRequestData: accessed-variable=rSR_DiagIOCtrlRequest.DiagIOCtrlRequestData
              DRP_rSR_DiagRoutineRequest_DiagRoutineRequestData: accessed-variable=rSR_DiagRoutineRequest.DiagRoutineRequestData
              DRA_rSR_DisplaySetPower_DisplaySetPowerData: accessed-variable=rSR_DisplaySetPower.DisplaySetPowerData
              DRA_rSR_FRTT_Status_FRTT_StatusData: accessed-variable=rSR_FRTT_Status.FRTT_StatusData
              DRA_rSR_FastGaugeInfo_FastGaugeInfoData: accessed-variable=rSR_FastGaugeInfo.FastGaugeInfoData
              DRP_rSR_HealthDumpGetData_HealthDumpGetDataData: accessed-variable=rSR_HealthDumpGetData.HealthDumpGetDataData
              DRP_rSR_HealthDumpGetHdr_HealthDumpGetHdrData: accessed-variable=rSR_HealthDumpGetHdr.HealthDumpGetHdrData
              DRA_rSR_HudWarningDisplay_HudWarningDisplayData: accessed-variable=rSR_HudWarningDisplay.HudWarningDisplayData
              DRP_rSR_IgnState_IgnStateData: accessed-variable=rSR_IgnState.IgnStateData
              DRA_rSR_IlluminationData_IlluminationDataData: accessed-variable=rSR_IlluminationData.IlluminationDataData
              DRA_rSR_PowerSystemStateReqChange_PowerSystemStateReqChangeData: accessed-variable=rSR_PowerSystemStateReqChange.PowerSystemStateReqChangeData
              DRA_rSR_RTT_Icon_RTT_IconData: accessed-variable=rSR_RTT_Icon.RTT_IconData
              DRA_rSR_RTT_Status_RTT_StatusData: accessed-variable=rSR_RTT_Status.RTT_StatusData
              DRA_rSR_RTT_Toggle_RTT_ToggleData: accessed-variable=rSR_RTT_Toggle.RTT_ToggleData
              DRA_rSR_ShiftPosIndStatus_ShiftPosIndStatusData: accessed-variable=rSR_ShiftPosIndStatus.ShiftPosIndStatusData
              DRA_rSR_SlowGaugeInfo_SlowGaugeInfoData: accessed-variable=rSR_SlowGaugeInfo.SlowGaugeInfoData
              DRA_rSR_TT_Status_TT_StatusData: accessed-variable=rSR_TT_Status.TT_StatusData
              DRA_rSR_TpmsWarningData_TpmsWarningDataData: accessed-variable=rSR_TpmsWarningData.TpmsWarningDataData
              DRA_rSR_WarningDisplay_WarningDisplayData: accessed-variable=rSR_WarningDisplay.WarningDisplayData
              DRA_rSR_WarningExtDisplay_WarningExtDisplayData: accessed-variable=rSR_WarningExtDisplay.WarningExtDisplayData
              DRP_rSR_UpdateLongServiceReq_UpdateLongServiceReqData: accessed-variable=rSR_UpdateLongServiceReq.UpdateLongServiceReqData
              DRP_rSR_UpdateShortServiceReq_UpdateShortServiceReqData: accessed-variable=rSR_UpdateShortServiceReq.UpdateShortServiceReqData
              DRA_rSR_DLTControlMessageReponse_DLTControlMessageReponseData: accessed-variable=rSR_DLTControlMessageReponse.DLTControlMessageReponseData
              DRA_rSR_DLTMessageReadRequest_DLTMessageReadRequestData: accessed-variable=rSR_DLTMessageReadRequest.DLTMessageReadRequestData
          data-send-points:
            19 x access:
              DWA_pSR_DisplayCurrentState_DisplayCurrentStateData: accessed-variable=pSR_DisplayCurrentState.DisplayCurrentStateData
              DWA_pSR_EmmcErrorNotifier_EmmcErrorNotifierData: accessed-variable=pSR_EmmcErrorNotifier.EmmcErrorNotifierData
              DSP_pSR_HealthDomainFatalError_HealthDomainFatalErrorData: accessed-variable=pSR_HealthDomainFatalError.HealthDomainFatalErrorData
              DSP_pSR_HealthDomainHeartbeat_HealthDomainHeartbeatData: accessed-variable=pSR_HealthDomainHeartbeat.HealthDomainHeartbeatData
              DSP_pSR_HealthDumpData_HealthDumpDataData: accessed-variable=pSR_HealthDumpData.HealthDumpDataData
              DSP_pSR_HealthDumpHdrInfo_HealthDumpHdrInfoData: accessed-variable=pSR_HealthDumpHdrInfo.HealthDumpHdrInfoData
              DSP_pSR_HealthEventRecord_HealthEventRecordData: accessed-variable=pSR_HealthEventRecord.HealthEventRecordData
              DWA_pSR_HudWarningStatus_HudWarningStatusData: accessed-variable=pSR_HudWarningStatus.HudWarningStatusData
              DSP_pSR_PowerExtendShutdownTime_PowerExtendShutdownTimeData: accessed-variable=pSR_PowerExtendShutdownTime.PowerExtendShutdownTimeData
              DSP_pSR_PowerKeepSystemAwake_PowerKeepSystemAwakeData: accessed-variable=pSR_PowerKeepSystemAwake.PowerKeepSystemAwakeData
              DWA_pSR_PowerSystemState_PowerSystemStateData: accessed-variable=pSR_PowerSystemState.PowerSystemStateData
              DWA_pSR_WarningDisplayAvailable_WarningDisplayAvailableData: accessed-variable=pSR_WarningDisplayAvailable.WarningDisplayAvailableData
              DWA_pSR_WarningStatus_WarningStatusData: accessed-variable=pSR_WarningStatus.WarningStatusData
              DSP_pSR_MainHMIReadyStatus_MainHMIReadyStatusData: accessed-variable=pSR_MainHMIReadyStatus.MainHMIReadyStatusData
              DSP_pSR_SafeHMIReadyStatus_SafeHMIReadyStatusData: accessed-variable=pSR_SafeHMIReadyStatus.SafeHMIReadyStatusData
              DSP_pSR_DiagResponse_DiagResponseData: accessed-variable=pSR_DiagResponse.DiagResponseData
              DSP_pSR_UpdateShortServiceResp_UpdateShortServiceRespData: accessed-variable=pSR_UpdateShortServiceResp.UpdateShortServiceRespData
              DWA_pSR_DLTControlMessageRequest_DLTControlMessageRequestData: accessed-variable=pSR_DLTControlMessageRequest.DLTControlMessageRequestData
              DWA_pSR_DLTMessageReadAck_DLTMessageReadAckData: accessed-variable=pSR_DLTMessageReadAck.DLTMessageReadAckData
          sync call OA_rCS_UclSystemCallbacks_ErrorNotification: operation=rCS_UclSystemCallbacks.ErrorNotification
          sync call OA_rCS_UclSystemCallbacks_LinkStatusChanged: operation=rCS_UclSystemCallbacks.LinkStatusChanged
        OnDre_UpdateShortServiceReq
          data-receive-point-by-arguments:
            25 x access:
              DRP_rSR_DiagDIDRequest_DiagDIDRequestData: accessed-variable=rSR_DiagDIDRequest.DiagDIDRequestData
              DRP_rSR_DiagIOCtrlRequest_DiagIOCtrlRequestData: accessed-variable=rSR_DiagIOCtrlRequest.DiagIOCtrlRequestData
              DRP_rSR_DiagRoutineRequest_DiagRoutineRequestData: accessed-variable=rSR_DiagRoutineRequest.DiagRoutineRequestData
              DRA_rSR_DisplaySetPower_DisplaySetPowerData: accessed-variable=rSR_DisplaySetPower.DisplaySetPowerData
              DRA_rSR_FRTT_Status_FRTT_StatusData: accessed-variable=rSR_FRTT_Status.FRTT_StatusData
              DRA_rSR_FastGaugeInfo_FastGaugeInfoData: accessed-variable=rSR_FastGaugeInfo.FastGaugeInfoData
              DRP_rSR_HealthDumpGetData_HealthDumpGetDataData: accessed-variable=rSR_HealthDumpGetData.HealthDumpGetDataData
              DRP_rSR_HealthDumpGetHdr_HealthDumpGetHdrData: accessed-variable=rSR_HealthDumpGetHdr.HealthDumpGetHdrData
              DRA_rSR_HudWarningDisplay_HudWarningDisplayData: accessed-variable=rSR_HudWarningDisplay.HudWarningDisplayData
              DRP_rSR_IgnState_IgnStateData: accessed-variable=rSR_IgnState.IgnStateData
              DRA_rSR_IlluminationData_IlluminationDataData: accessed-variable=rSR_IlluminationData.IlluminationDataData
              DRA_rSR_PowerSystemStateReqChange_PowerSystemStateReqChangeData: accessed-variable=rSR_PowerSystemStateReqChange.PowerSystemStateReqChangeData
              DRA_rSR_RTT_Icon_RTT_IconData: accessed-variable=rSR_RTT_Icon.RTT_IconData
              DRA_rSR_RTT_Status_RTT_StatusData: accessed-variable=rSR_RTT_Status.RTT_StatusData
              DRA_rSR_RTT_Toggle_RTT_ToggleData: accessed-variable=rSR_RTT_Toggle.RTT_ToggleData
              DRA_rSR_ShiftPosIndStatus_ShiftPosIndStatusData: accessed-variable=rSR_ShiftPosIndStatus.ShiftPosIndStatusData
              DRA_rSR_SlowGaugeInfo_SlowGaugeInfoData: accessed-variable=rSR_SlowGaugeInfo.SlowGaugeInfoData
              DRA_rSR_TT_Status_TT_StatusData: accessed-variable=rSR_TT_Status.TT_StatusData
              DRA_rSR_TpmsWarningData_TpmsWarningDataData: accessed-variable=rSR_TpmsWarningData.TpmsWarningDataData
              DRA_rSR_WarningDisplay_WarningDisplayData: accessed-variable=rSR_WarningDisplay.WarningDisplayData
              DRA_rSR_WarningExtDisplay_WarningExtDisplayData: accessed-variable=rSR_WarningExtDisplay.WarningExtDisplayData
              DRP_rSR_UpdateLongServiceReq_UpdateLongServiceReqData: accessed-variable=rSR_UpdateLongServiceReq.UpdateLongServiceReqData
              DRP_rSR_UpdateShortServiceReq_UpdateShortServiceReqData: accessed-variable=rSR_UpdateShortServiceReq.UpdateShortServiceReqData
              DRA_rSR_DLTControlMessageReponse_DLTControlMessageReponseData: accessed-variable=rSR_DLTControlMessageReponse.DLTControlMessageReponseData
              DRA_rSR_DLTMessageReadRequest_DLTMessageReadRequestData: accessed-variable=rSR_DLTMessageReadRequest.DLTMessageReadRequestData
          data-send-points:
            19 x access:
              DWA_pSR_DisplayCurrentState_DisplayCurrentStateData: accessed-variable=pSR_DisplayCurrentState.DisplayCurrentStateData
              DWA_pSR_EmmcErrorNotifier_EmmcErrorNotifierData: accessed-variable=pSR_EmmcErrorNotifier.EmmcErrorNotifierData
              DSP_pSR_HealthDomainFatalError_HealthDomainFatalErrorData: accessed-variable=pSR_HealthDomainFatalError.HealthDomainFatalErrorData
              DSP_pSR_HealthDomainHeartbeat_HealthDomainHeartbeatData: accessed-variable=pSR_HealthDomainHeartbeat.HealthDomainHeartbeatData
              DSP_pSR_HealthDumpData_HealthDumpDataData: accessed-variable=pSR_HealthDumpData.HealthDumpDataData
              DSP_pSR_HealthDumpHdrInfo_HealthDumpHdrInfoData: accessed-variable=pSR_HealthDumpHdrInfo.HealthDumpHdrInfoData
              DSP_pSR_HealthEventRecord_HealthEventRecordData: accessed-variable=pSR_HealthEventRecord.HealthEventRecordData
              DWA_pSR_HudWarningStatus_HudWarningStatusData: accessed-variable=pSR_HudWarningStatus.HudWarningStatusData
              DSP_pSR_PowerExtendShutdownTime_PowerExtendShutdownTimeData: accessed-variable=pSR_PowerExtendShutdownTime.PowerExtendShutdownTimeData
              DSP_pSR_PowerKeepSystemAwake_PowerKeepSystemAwakeData: accessed-variable=pSR_PowerKeepSystemAwake.PowerKeepSystemAwakeData
              DWA_pSR_PowerSystemState_PowerSystemStateData: accessed-variable=pSR_PowerSystemState.PowerSystemStateData
              DWA_pSR_WarningDisplayAvailable_WarningDisplayAvailableData: accessed-variable=pSR_WarningDisplayAvailable.WarningDisplayAvailableData
              DWA_pSR_WarningStatus_WarningStatusData: accessed-variable=pSR_WarningStatus.WarningStatusData
              DSP_pSR_MainHMIReadyStatus_MainHMIReadyStatusData: accessed-variable=pSR_MainHMIReadyStatus.MainHMIReadyStatusData
              DSP_pSR_SafeHMIReadyStatus_SafeHMIReadyStatusData: accessed-variable=pSR_SafeHMIReadyStatus.SafeHMIReadyStatusData
              DSP_pSR_DiagResponse_DiagResponseData: accessed-variable=pSR_DiagResponse.DiagResponseData
              DSP_pSR_UpdateShortServiceResp_UpdateShortServiceRespData: accessed-variable=pSR_UpdateShortServiceResp.UpdateShortServiceRespData
              DWA_pSR_DLTControlMessageRequest_DLTControlMessageRequestData: accessed-variable=pSR_DLTControlMessageRequest.DLTControlMessageRequestData
              DWA_pSR_DLTMessageReadAck_DLTMessageReadAckData: accessed-variable=pSR_DLTMessageReadAck.DLTMessageReadAckData
          sync call OA_rCS_UclSystemCallbacks_ErrorNotification: operation=rCS_UclSystemCallbacks.ErrorNotification
          sync call OA_rCS_UclSystemCallbacks_LinkStatusChanged: operation=rCS_UclSystemCallbacks.LinkStatusChanged
        OnDre_WarningDisplay
          data-receive-point-by-arguments:
            25 x access:
              DRP_rSR_DiagDIDRequest_DiagDIDRequestData: accessed-variable=rSR_DiagDIDRequest.DiagDIDRequestData
              DRP_rSR_DiagIOCtrlRequest_DiagIOCtrlRequestData: accessed-variable=rSR_DiagIOCtrlRequest.DiagIOCtrlRequestData
              DRP_rSR_DiagRoutineRequest_DiagRoutineRequestData: accessed-variable=rSR_DiagRoutineRequest.DiagRoutineRequestData
              DRA_rSR_DisplaySetPower_DisplaySetPowerData: accessed-variable=rSR_DisplaySetPower.DisplaySetPowerData
              DRA_rSR_FRTT_Status_FRTT_StatusData: accessed-variable=rSR_FRTT_Status.FRTT_StatusData
              DRA_rSR_FastGaugeInfo_FastGaugeInfoData: accessed-variable=rSR_FastGaugeInfo.FastGaugeInfoData
              DRP_rSR_HealthDumpGetData_HealthDumpGetDataData: accessed-variable=rSR_HealthDumpGetData.HealthDumpGetDataData
              DRP_rSR_HealthDumpGetHdr_HealthDumpGetHdrData: accessed-variable=rSR_HealthDumpGetHdr.HealthDumpGetHdrData
              DRA_rSR_HudWarningDisplay_HudWarningDisplayData: accessed-variable=rSR_HudWarningDisplay.HudWarningDisplayData
              DRP_rSR_IgnState_IgnStateData: accessed-variable=rSR_IgnState.IgnStateData
              DRA_rSR_IlluminationData_IlluminationDataData: accessed-variable=rSR_IlluminationData.IlluminationDataData
              DRA_rSR_PowerSystemStateReqChange_PowerSystemStateReqChangeData: accessed-variable=rSR_PowerSystemStateReqChange.PowerSystemStateReqChangeData
              DRA_rSR_RTT_Icon_RTT_IconData: accessed-variable=rSR_RTT_Icon.RTT_IconData
              DRA_rSR_RTT_Status_RTT_StatusData: accessed-variable=rSR_RTT_Status.RTT_StatusData
              DRA_rSR_RTT_Toggle_RTT_ToggleData: accessed-variable=rSR_RTT_Toggle.RTT_ToggleData
              DRA_rSR_ShiftPosIndStatus_ShiftPosIndStatusData: accessed-variable=rSR_ShiftPosIndStatus.ShiftPosIndStatusData
              DRA_rSR_SlowGaugeInfo_SlowGaugeInfoData: accessed-variable=rSR_SlowGaugeInfo.SlowGaugeInfoData
              DRA_rSR_TT_Status_TT_StatusData: accessed-variable=rSR_TT_Status.TT_StatusData
              DRA_rSR_TpmsWarningData_TpmsWarningDataData: accessed-variable=rSR_TpmsWarningData.TpmsWarningDataData
              DRA_rSR_WarningDisplay_WarningDisplayData: accessed-variable=rSR_WarningDisplay.WarningDisplayData
              DRA_rSR_WarningExtDisplay_WarningExtDisplayData: accessed-variable=rSR_WarningExtDisplay.WarningExtDisplayData
              DRP_rSR_UpdateLongServiceReq_UpdateLongServiceReqData: accessed-variable=rSR_UpdateLongServiceReq.UpdateLongServiceReqData
              DRP_rSR_UpdateShortServiceReq_UpdateShortServiceReqData: accessed-variable=rSR_UpdateShortServiceReq.UpdateShortServiceReqData
              DRA_rSR_DLTControlMessageReponse_DLTControlMessageReponseData: accessed-variable=rSR_DLTControlMessageReponse.DLTControlMessageReponseData
              DRA_rSR_DLTMessageReadRequest_DLTMessageReadRequestData: accessed-variable=rSR_DLTMessageReadRequest.DLTMessageReadRequestData
          data-send-points:
            19 x access:
              DWA_pSR_DisplayCurrentState_DisplayCurrentStateData: accessed-variable=pSR_DisplayCurrentState.DisplayCurrentStateData
              DWA_pSR_EmmcErrorNotifier_EmmcErrorNotifierData: accessed-variable=pSR_EmmcErrorNotifier.EmmcErrorNotifierData
              DSP_pSR_HealthDomainFatalError_HealthDomainFatalErrorData: accessed-variable=pSR_HealthDomainFatalError.HealthDomainFatalErrorData
              DSP_pSR_HealthDomainHeartbeat_HealthDomainHeartbeatData: accessed-variable=pSR_HealthDomainHeartbeat.HealthDomainHeartbeatData
              DSP_pSR_HealthDumpData_HealthDumpDataData: accessed-variable=pSR_HealthDumpData.HealthDumpDataData
              DSP_pSR_HealthDumpHdrInfo_HealthDumpHdrInfoData: accessed-variable=pSR_HealthDumpHdrInfo.HealthDumpHdrInfoData
              DSP_pSR_HealthEventRecord_HealthEventRecordData: accessed-variable=pSR_HealthEventRecord.HealthEventRecordData
              DWA_pSR_HudWarningStatus_HudWarningStatusData: accessed-variable=pSR_HudWarningStatus.HudWarningStatusData
              DSP_pSR_PowerExtendShutdownTime_PowerExtendShutdownTimeData: accessed-variable=pSR_PowerExtendShutdownTime.PowerExtendShutdownTimeData
              DSP_pSR_PowerKeepSystemAwake_PowerKeepSystemAwakeData: accessed-variable=pSR_PowerKeepSystemAwake.PowerKeepSystemAwakeData
              DWA_pSR_PowerSystemState_PowerSystemStateData: accessed-variable=pSR_PowerSystemState.PowerSystemStateData
              DWA_pSR_WarningDisplayAvailable_WarningDisplayAvailableData: accessed-variable=pSR_WarningDisplayAvailable.WarningDisplayAvailableData
              DWA_pSR_WarningStatus_WarningStatusData: accessed-variable=pSR_WarningStatus.WarningStatusData
              DSP_pSR_MainHMIReadyStatus_MainHMIReadyStatusData: accessed-variable=pSR_MainHMIReadyStatus.MainHMIReadyStatusData
              DSP_pSR_SafeHMIReadyStatus_SafeHMIReadyStatusData: accessed-variable=pSR_SafeHMIReadyStatus.SafeHMIReadyStatusData
              DSP_pSR_DiagResponse_DiagResponseData: accessed-variable=pSR_DiagResponse.DiagResponseData
              DSP_pSR_UpdateShortServiceResp_UpdateShortServiceRespData: accessed-variable=pSR_UpdateShortServiceResp.UpdateShortServiceRespData
              DWA_pSR_DLTControlMessageRequest_DLTControlMessageRequestData: accessed-variable=pSR_DLTControlMessageRequest.DLTControlMessageRequestData
              DWA_pSR_DLTMessageReadAck_DLTMessageReadAckData: accessed-variable=pSR_DLTMessageReadAck.DLTMessageReadAckData
          sync call OA_rCS_UclSystemCallbacks_ErrorNotification: operation=rCS_UclSystemCallbacks.ErrorNotification
          sync call OA_rCS_UclSystemCallbacks_LinkStatusChanged: operation=rCS_UclSystemCallbacks.LinkStatusChanged
        OnDre_WarningExtDisplay
          data-receive-point-by-arguments:
            25 x access:
              DRP_rSR_DiagDIDRequest_DiagDIDRequestData: accessed-variable=rSR_DiagDIDRequest.DiagDIDRequestData
              DRP_rSR_DiagIOCtrlRequest_DiagIOCtrlRequestData: accessed-variable=rSR_DiagIOCtrlRequest.DiagIOCtrlRequestData
              DRP_rSR_DiagRoutineRequest_DiagRoutineRequestData: accessed-variable=rSR_DiagRoutineRequest.DiagRoutineRequestData
              DRA_rSR_DisplaySetPower_DisplaySetPowerData: accessed-variable=rSR_DisplaySetPower.DisplaySetPowerData
              DRA_rSR_FRTT_Status_FRTT_StatusData: accessed-variable=rSR_FRTT_Status.FRTT_StatusData
              DRA_rSR_FastGaugeInfo_FastGaugeInfoData: accessed-variable=rSR_FastGaugeInfo.FastGaugeInfoData
              DRP_rSR_HealthDumpGetData_HealthDumpGetDataData: accessed-variable=rSR_HealthDumpGetData.HealthDumpGetDataData
              DRP_rSR_HealthDumpGetHdr_HealthDumpGetHdrData: accessed-variable=rSR_HealthDumpGetHdr.HealthDumpGetHdrData
              DRA_rSR_HudWarningDisplay_HudWarningDisplayData: accessed-variable=rSR_HudWarningDisplay.HudWarningDisplayData
              DRP_rSR_IgnState_IgnStateData: accessed-variable=rSR_IgnState.IgnStateData
              DRA_rSR_IlluminationData_IlluminationDataData: accessed-variable=rSR_IlluminationData.IlluminationDataData
              DRA_rSR_PowerSystemStateReqChange_PowerSystemStateReqChangeData: accessed-variable=rSR_PowerSystemStateReqChange.PowerSystemStateReqChangeData
              DRA_rSR_RTT_Icon_RTT_IconData: accessed-variable=rSR_RTT_Icon.RTT_IconData
              DRA_rSR_RTT_Status_RTT_StatusData: accessed-variable=rSR_RTT_Status.RTT_StatusData
              DRA_rSR_RTT_Toggle_RTT_ToggleData: accessed-variable=rSR_RTT_Toggle.RTT_ToggleData
              DRA_rSR_ShiftPosIndStatus_ShiftPosIndStatusData: accessed-variable=rSR_ShiftPosIndStatus.ShiftPosIndStatusData
              DRA_rSR_SlowGaugeInfo_SlowGaugeInfoData: accessed-variable=rSR_SlowGaugeInfo.SlowGaugeInfoData
              DRA_rSR_TT_Status_TT_StatusData: accessed-variable=rSR_TT_Status.TT_StatusData
              DRA_rSR_TpmsWarningData_TpmsWarningDataData: accessed-variable=rSR_TpmsWarningData.TpmsWarningDataData
              DRA_rSR_WarningDisplay_WarningDisplayData: accessed-variable=rSR_WarningDisplay.WarningDisplayData
              DRA_rSR_WarningExtDisplay_WarningExtDisplayData: accessed-variable=rSR_WarningExtDisplay.WarningExtDisplayData
              DRP_rSR_UpdateLongServiceReq_UpdateLongServiceReqData: accessed-variable=rSR_UpdateLongServiceReq.UpdateLongServiceReqData
              DRP_rSR_UpdateShortServiceReq_UpdateShortServiceReqData: accessed-variable=rSR_UpdateShortServiceReq.UpdateShortServiceReqData
              DRA_rSR_DLTControlMessageReponse_DLTControlMessageReponseData: accessed-variable=rSR_DLTControlMessageReponse.DLTControlMessageReponseData
              DRA_rSR_DLTMessageReadRequest_DLTMessageReadRequestData: accessed-variable=rSR_DLTMessageReadRequest.DLTMessageReadRequestData
          data-send-points:
            19 x access:
              DWA_pSR_DisplayCurrentState_DisplayCurrentStateData: accessed-variable=pSR_DisplayCurrentState.DisplayCurrentStateData
              DWA_pSR_EmmcErrorNotifier_EmmcErrorNotifierData: accessed-variable=pSR_EmmcErrorNotifier.EmmcErrorNotifierData
              DSP_pSR_HealthDomainFatalError_HealthDomainFatalErrorData: accessed-variable=pSR_HealthDomainFatalError.HealthDomainFatalErrorData
              DSP_pSR_HealthDomainHeartbeat_HealthDomainHeartbeatData: accessed-variable=pSR_HealthDomainHeartbeat.HealthDomainHeartbeatData
              DSP_pSR_HealthDumpData_HealthDumpDataData: accessed-variable=pSR_HealthDumpData.HealthDumpDataData
              DSP_pSR_HealthDumpHdrInfo_HealthDumpHdrInfoData: accessed-variable=pSR_HealthDumpHdrInfo.HealthDumpHdrInfoData
              DSP_pSR_HealthEventRecord_HealthEventRecordData: accessed-variable=pSR_HealthEventRecord.HealthEventRecordData
              DWA_pSR_HudWarningStatus_HudWarningStatusData: accessed-variable=pSR_HudWarningStatus.HudWarningStatusData
              DSP_pSR_PowerExtendShutdownTime_PowerExtendShutdownTimeData: accessed-variable=pSR_PowerExtendShutdownTime.PowerExtendShutdownTimeData
              DSP_pSR_PowerKeepSystemAwake_PowerKeepSystemAwakeData: accessed-variable=pSR_PowerKeepSystemAwake.PowerKeepSystemAwakeData
              DWA_pSR_PowerSystemState_PowerSystemStateData: accessed-variable=pSR_PowerSystemState.PowerSystemStateData
              DWA_pSR_WarningDisplayAvailable_WarningDisplayAvailableData: accessed-variable=pSR_WarningDisplayAvailable.WarningDisplayAvailableData
              DWA_pSR_WarningStatus_WarningStatusData: accessed-variable=pSR_WarningStatus.WarningStatusData
              DSP_pSR_MainHMIReadyStatus_MainHMIReadyStatusData: accessed-variable=pSR_MainHMIReadyStatus.MainHMIReadyStatusData
              DSP_pSR_SafeHMIReadyStatus_SafeHMIReadyStatusData: accessed-variable=pSR_SafeHMIReadyStatus.SafeHMIReadyStatusData
              DSP_pSR_DiagResponse_DiagResponseData: accessed-variable=pSR_DiagResponse.DiagResponseData
              DSP_pSR_UpdateShortServiceResp_UpdateShortServiceRespData: accessed-variable=pSR_UpdateShortServiceResp.UpdateShortServiceRespData
              DWA_pSR_DLTControlMessageRequest_DLTControlMessageRequestData: accessed-variable=pSR_DLTControlMessageRequest.DLTControlMessageRequestData
              DWA_pSR_DLTMessageReadAck_DLTMessageReadAckData: accessed-variable=pSR_DLTMessageReadAck.DLTMessageReadAckData
          sync call OA_rCS_UclSystemCallbacks_ErrorNotification: operation=rCS_UclSystemCallbacks.ErrorNotification
          sync call OA_rCS_UclSystemCallbacks_LinkStatusChanged: operation=rCS_UclSystemCallbacks.LinkStatusChanged
        OnDre_DiagDIDRequest
          data-receive-point-by-arguments:
            25 x access:
              DRP_rSR_DiagDIDRequest_DiagDIDRequestData: accessed-variable=rSR_DiagDIDRequest.DiagDIDRequestData
              DRP_rSR_DiagIOCtrlRequest_DiagIOCtrlRequestData: accessed-variable=rSR_DiagIOCtrlRequest.DiagIOCtrlRequestData
              DRP_rSR_DiagRoutineRequest_DiagRoutineRequestData: accessed-variable=rSR_DiagRoutineRequest.DiagRoutineRequestData
              DRA_rSR_DisplaySetPower_DisplaySetPowerData: accessed-variable=rSR_DisplaySetPower.DisplaySetPowerData
              DRA_rSR_FRTT_Status_FRTT_StatusData: accessed-variable=rSR_FRTT_Status.FRTT_StatusData
              DRA_rSR_FastGaugeInfo_FastGaugeInfoData: accessed-variable=rSR_FastGaugeInfo.FastGaugeInfoData
              DRP_rSR_HealthDumpGetData_HealthDumpGetDataData: accessed-variable=rSR_HealthDumpGetData.HealthDumpGetDataData
              DRP_rSR_HealthDumpGetHdr_HealthDumpGetHdrData: accessed-variable=rSR_HealthDumpGetHdr.HealthDumpGetHdrData
              DRA_rSR_HudWarningDisplay_HudWarningDisplayData: accessed-variable=rSR_HudWarningDisplay.HudWarningDisplayData
              DRP_rSR_IgnState_IgnStateData: accessed-variable=rSR_IgnState.IgnStateData
              DRA_rSR_IlluminationData_IlluminationDataData: accessed-variable=rSR_IlluminationData.IlluminationDataData
              DRA_rSR_PowerSystemStateReqChange_PowerSystemStateReqChangeData: accessed-variable=rSR_PowerSystemStateReqChange.PowerSystemStateReqChangeData
              DRA_rSR_RTT_Icon_RTT_IconData: accessed-variable=rSR_RTT_Icon.RTT_IconData
              DRA_rSR_RTT_Status_RTT_StatusData: accessed-variable=rSR_RTT_Status.RTT_StatusData
              DRA_rSR_RTT_Toggle_RTT_ToggleData: accessed-variable=rSR_RTT_Toggle.RTT_ToggleData
              DRA_rSR_ShiftPosIndStatus_ShiftPosIndStatusData: accessed-variable=rSR_ShiftPosIndStatus.ShiftPosIndStatusData
              DRA_rSR_SlowGaugeInfo_SlowGaugeInfoData: accessed-variable=rSR_SlowGaugeInfo.SlowGaugeInfoData
              DRA_rSR_TT_Status_TT_StatusData: accessed-variable=rSR_TT_Status.TT_StatusData
              DRA_rSR_TpmsWarningData_TpmsWarningDataData: accessed-variable=rSR_TpmsWarningData.TpmsWarningDataData
              DRP_rSR_UpdateLongServiceReq_UpdateLongServiceReqData: accessed-variable=rSR_UpdateLongServiceReq.UpdateLongServiceReqData
              DRP_rSR_UpdateShortServiceReq_UpdateShortServiceReqData: accessed-variable=rSR_UpdateShortServiceReq.UpdateShortServiceReqData
              DRA_rSR_WarningDisplay_WarningDisplayData: accessed-variable=rSR_WarningDisplay.WarningDisplayData
              DRA_rSR_WarningExtDisplay_WarningExtDisplayData: accessed-variable=rSR_WarningExtDisplay.WarningExtDisplayData
              DRA_rSR_DLTControlMessageReponse_DLTControlMessageReponseData: accessed-variable=rSR_DLTControlMessageReponse.DLTControlMessageReponseData
              DRA_rSR_DLTMessageReadRequest_DLTMessageReadRequestData: accessed-variable=rSR_DLTMessageReadRequest.DLTMessageReadRequestData
          data-send-points:
            19 x access:
              DSP_pSR_DiagResponse_DiagResponseData: accessed-variable=pSR_DiagResponse.DiagResponseData
              DWA_pSR_DisplayCurrentState_DisplayCurrentStateData: accessed-variable=pSR_DisplayCurrentState.DisplayCurrentStateData
              DWA_pSR_EmmcErrorNotifier_EmmcErrorNotifierData: accessed-variable=pSR_EmmcErrorNotifier.EmmcErrorNotifierData
              DSP_pSR_HealthDomainFatalError_HealthDomainFatalErrorData: accessed-variable=pSR_HealthDomainFatalError.HealthDomainFatalErrorData
              DSP_pSR_HealthDomainHeartbeat_HealthDomainHeartbeatData: accessed-variable=pSR_HealthDomainHeartbeat.HealthDomainHeartbeatData
              DSP_pSR_HealthDumpData_HealthDumpDataData: accessed-variable=pSR_HealthDumpData.HealthDumpDataData
              DSP_pSR_HealthDumpHdrInfo_HealthDumpHdrInfoData: accessed-variable=pSR_HealthDumpHdrInfo.HealthDumpHdrInfoData
              DSP_pSR_HealthEventRecord_HealthEventRecordData: accessed-variable=pSR_HealthEventRecord.HealthEventRecordData
              DWA_pSR_HudWarningStatus_HudWarningStatusData: accessed-variable=pSR_HudWarningStatus.HudWarningStatusData
              DSP_pSR_MainHMIReadyStatus_MainHMIReadyStatusData: accessed-variable=pSR_MainHMIReadyStatus.MainHMIReadyStatusData
              DSP_pSR_PowerExtendShutdownTime_PowerExtendShutdownTimeData: accessed-variable=pSR_PowerExtendShutdownTime.PowerExtendShutdownTimeData
              DSP_pSR_PowerKeepSystemAwake_PowerKeepSystemAwakeData: accessed-variable=pSR_PowerKeepSystemAwake.PowerKeepSystemAwakeData
              DWA_pSR_PowerSystemState_PowerSystemStateData: accessed-variable=pSR_PowerSystemState.PowerSystemStateData
              DSP_pSR_SafeHMIReadyStatus_SafeHMIReadyStatusData: accessed-variable=pSR_SafeHMIReadyStatus.SafeHMIReadyStatusData
              DSP_pSR_UpdateShortServiceResp_UpdateShortServiceRespData: accessed-variable=pSR_UpdateShortServiceResp.UpdateShortServiceRespData
              DWA_pSR_WarningDisplayAvailable_WarningDisplayAvailableData: accessed-variable=pSR_WarningDisplayAvailable.WarningDisplayAvailableData
              DWA_pSR_WarningStatus_WarningStatusData: accessed-variable=pSR_WarningStatus.WarningStatusData
              DWA_pSR_DLTControlMessageRequest_DLTControlMessageRequestData: accessed-variable=pSR_DLTControlMessageRequest.DLTControlMessageRequestData
              DWA_pSR_DLTMessageReadAck_DLTMessageReadAckData: accessed-variable=pSR_DLTMessageReadAck.DLTMessageReadAckData
          sync call OA_rCS_UclSystemCallbacks_ErrorNotification: operation=rCS_UclSystemCallbacks.ErrorNotification
          sync call OA_rCS_UclSystemCallbacks_LinkStatusChanged: operation=rCS_UclSystemCallbacks.LinkStatusChanged
        OnDre_DiagIOCtrlRequest
          data-receive-point-by-arguments:
            25 x access:
              DRP_rSR_DiagDIDRequest_DiagDIDRequestData: accessed-variable=rSR_DiagDIDRequest.DiagDIDRequestData
              DRP_rSR_DiagIOCtrlRequest_DiagIOCtrlRequestData: accessed-variable=rSR_DiagIOCtrlRequest.DiagIOCtrlRequestData
              DRP_rSR_DiagRoutineRequest_DiagRoutineRequestData: accessed-variable=rSR_DiagRoutineRequest.DiagRoutineRequestData
              DRA_rSR_DisplaySetPower_DisplaySetPowerData: accessed-variable=rSR_DisplaySetPower.DisplaySetPowerData
              DRA_rSR_FRTT_Status_FRTT_StatusData: accessed-variable=rSR_FRTT_Status.FRTT_StatusData
              DRA_rSR_FastGaugeInfo_FastGaugeInfoData: accessed-variable=rSR_FastGaugeInfo.FastGaugeInfoData
              DRP_rSR_HealthDumpGetData_HealthDumpGetDataData: accessed-variable=rSR_HealthDumpGetData.HealthDumpGetDataData
              DRP_rSR_HealthDumpGetHdr_HealthDumpGetHdrData: accessed-variable=rSR_HealthDumpGetHdr.HealthDumpGetHdrData
              DRA_rSR_HudWarningDisplay_HudWarningDisplayData: accessed-variable=rSR_HudWarningDisplay.HudWarningDisplayData
              DRP_rSR_IgnState_IgnStateData: accessed-variable=rSR_IgnState.IgnStateData
              DRA_rSR_IlluminationData_IlluminationDataData: accessed-variable=rSR_IlluminationData.IlluminationDataData
              DRA_rSR_PowerSystemStateReqChange_PowerSystemStateReqChangeData: accessed-variable=rSR_PowerSystemStateReqChange.PowerSystemStateReqChangeData
              DRA_rSR_RTT_Icon_RTT_IconData: accessed-variable=rSR_RTT_Icon.RTT_IconData
              DRA_rSR_RTT_Status_RTT_StatusData: accessed-variable=rSR_RTT_Status.RTT_StatusData
              DRA_rSR_RTT_Toggle_RTT_ToggleData: accessed-variable=rSR_RTT_Toggle.RTT_ToggleData
              DRA_rSR_ShiftPosIndStatus_ShiftPosIndStatusData: accessed-variable=rSR_ShiftPosIndStatus.ShiftPosIndStatusData
              DRA_rSR_SlowGaugeInfo_SlowGaugeInfoData: accessed-variable=rSR_SlowGaugeInfo.SlowGaugeInfoData
              DRA_rSR_TT_Status_TT_StatusData: accessed-variable=rSR_TT_Status.TT_StatusData
              DRA_rSR_TpmsWarningData_TpmsWarningDataData: accessed-variable=rSR_TpmsWarningData.TpmsWarningDataData
              DRP_rSR_UpdateLongServiceReq_UpdateLongServiceReqData: accessed-variable=rSR_UpdateLongServiceReq.UpdateLongServiceReqData
              DRP_rSR_UpdateShortServiceReq_UpdateShortServiceReqData: accessed-variable=rSR_UpdateShortServiceReq.UpdateShortServiceReqData
              DRA_rSR_WarningDisplay_WarningDisplayData: accessed-variable=rSR_WarningDisplay.WarningDisplayData
              DRA_rSR_WarningExtDisplay_WarningExtDisplayData: accessed-variable=rSR_WarningExtDisplay.WarningExtDisplayData
              DRA_rSR_DLTControlMessageReponse_DLTControlMessageReponseData: accessed-variable=rSR_DLTControlMessageReponse.DLTControlMessageReponseData
              DRA_rSR_DLTMessageReadRequest_DLTMessageReadRequestData: accessed-variable=rSR_DLTMessageReadRequest.DLTMessageReadRequestData
          data-send-points:
            19 x access:
              DSP_pSR_DiagResponse_DiagResponseData: accessed-variable=pSR_DiagResponse.DiagResponseData
              DWA_pSR_DisplayCurrentState_DisplayCurrentStateData: accessed-variable=pSR_DisplayCurrentState.DisplayCurrentStateData
              DWA_pSR_EmmcErrorNotifier_EmmcErrorNotifierData: accessed-variable=pSR_EmmcErrorNotifier.EmmcErrorNotifierData
              DSP_pSR_HealthDomainFatalError_HealthDomainFatalErrorData: accessed-variable=pSR_HealthDomainFatalError.HealthDomainFatalErrorData
              DSP_pSR_HealthDomainHeartbeat_HealthDomainHeartbeatData: accessed-variable=pSR_HealthDomainHeartbeat.HealthDomainHeartbeatData
              DSP_pSR_HealthDumpData_HealthDumpDataData: accessed-variable=pSR_HealthDumpData.HealthDumpDataData
              DSP_pSR_HealthDumpHdrInfo_HealthDumpHdrInfoData: accessed-variable=pSR_HealthDumpHdrInfo.HealthDumpHdrInfoData
              DSP_pSR_HealthEventRecord_HealthEventRecordData: accessed-variable=pSR_HealthEventRecord.HealthEventRecordData
              DWA_pSR_HudWarningStatus_HudWarningStatusData: accessed-variable=pSR_HudWarningStatus.HudWarningStatusData
              DSP_pSR_MainHMIReadyStatus_MainHMIReadyStatusData: accessed-variable=pSR_MainHMIReadyStatus.MainHMIReadyStatusData
              DSP_pSR_PowerExtendShutdownTime_PowerExtendShutdownTimeData: accessed-variable=pSR_PowerExtendShutdownTime.PowerExtendShutdownTimeData
              DSP_pSR_PowerKeepSystemAwake_PowerKeepSystemAwakeData: accessed-variable=pSR_PowerKeepSystemAwake.PowerKeepSystemAwakeData
              DWA_pSR_PowerSystemState_PowerSystemStateData: accessed-variable=pSR_PowerSystemState.PowerSystemStateData
              DSP_pSR_SafeHMIReadyStatus_SafeHMIReadyStatusData: accessed-variable=pSR_SafeHMIReadyStatus.SafeHMIReadyStatusData
              DSP_pSR_UpdateShortServiceResp_UpdateShortServiceRespData: accessed-variable=pSR_UpdateShortServiceResp.UpdateShortServiceRespData
              DWA_pSR_WarningDisplayAvailable_WarningDisplayAvailableData: accessed-variable=pSR_WarningDisplayAvailable.WarningDisplayAvailableData
              DWA_pSR_WarningStatus_WarningStatusData: accessed-variable=pSR_WarningStatus.WarningStatusData
              DWA_pSR_DLTControlMessageRequest_DLTControlMessageRequestData: accessed-variable=pSR_DLTControlMessageRequest.DLTControlMessageRequestData
              DWA_pSR_DLTMessageReadAck_DLTMessageReadAckData: accessed-variable=pSR_DLTMessageReadAck.DLTMessageReadAckData
          sync call OA_rCS_UclSystemCallbacks_ErrorNotification: operation=rCS_UclSystemCallbacks.ErrorNotification
          sync call OA_rCS_UclSystemCallbacks_LinkStatusChanged: operation=rCS_UclSystemCallbacks.LinkStatusChanged
        OnDre_DiagRoutineRequest
          data-receive-point-by-arguments:
            25 x access:
              DRP_rSR_DiagDIDRequest_DiagDIDRequestData: accessed-variable=rSR_DiagDIDRequest.DiagDIDRequestData
              DRP_rSR_DiagIOCtrlRequest_DiagIOCtrlRequestData: accessed-variable=rSR_DiagIOCtrlRequest.DiagIOCtrlRequestData
              DRP_rSR_DiagRoutineRequest_DiagRoutineRequestData: accessed-variable=rSR_DiagRoutineRequest.DiagRoutineRequestData
              DRA_rSR_DisplaySetPower_DisplaySetPowerData: accessed-variable=rSR_DisplaySetPower.DisplaySetPowerData
              DRA_rSR_FRTT_Status_FRTT_StatusData: accessed-variable=rSR_FRTT_Status.FRTT_StatusData
              DRA_rSR_FastGaugeInfo_FastGaugeInfoData: accessed-variable=rSR_FastGaugeInfo.FastGaugeInfoData
              DRP_rSR_HealthDumpGetData_HealthDumpGetDataData: accessed-variable=rSR_HealthDumpGetData.HealthDumpGetDataData
              DRP_rSR_HealthDumpGetHdr_HealthDumpGetHdrData: accessed-variable=rSR_HealthDumpGetHdr.HealthDumpGetHdrData
              DRA_rSR_HudWarningDisplay_HudWarningDisplayData: accessed-variable=rSR_HudWarningDisplay.HudWarningDisplayData
              DRP_rSR_IgnState_IgnStateData: accessed-variable=rSR_IgnState.IgnStateData
              DRA_rSR_IlluminationData_IlluminationDataData: accessed-variable=rSR_IlluminationData.IlluminationDataData
              DRA_rSR_PowerSystemStateReqChange_PowerSystemStateReqChangeData: accessed-variable=rSR_PowerSystemStateReqChange.PowerSystemStateReqChangeData
              DRA_rSR_RTT_Icon_RTT_IconData: accessed-variable=rSR_RTT_Icon.RTT_IconData
              DRA_rSR_RTT_Status_RTT_StatusData: accessed-variable=rSR_RTT_Status.RTT_StatusData
              DRA_rSR_RTT_Toggle_RTT_ToggleData: accessed-variable=rSR_RTT_Toggle.RTT_ToggleData
              DRA_rSR_ShiftPosIndStatus_ShiftPosIndStatusData: accessed-variable=rSR_ShiftPosIndStatus.ShiftPosIndStatusData
              DRA_rSR_SlowGaugeInfo_SlowGaugeInfoData: accessed-variable=rSR_SlowGaugeInfo.SlowGaugeInfoData
              DRA_rSR_TT_Status_TT_StatusData: accessed-variable=rSR_TT_Status.TT_StatusData
              DRA_rSR_TpmsWarningData_TpmsWarningDataData: accessed-variable=rSR_TpmsWarningData.TpmsWarningDataData
              DRP_rSR_UpdateLongServiceReq_UpdateLongServiceReqData: accessed-variable=rSR_UpdateLongServiceReq.UpdateLongServiceReqData
              DRP_rSR_UpdateShortServiceReq_UpdateShortServiceReqData: accessed-variable=rSR_UpdateShortServiceReq.UpdateShortServiceReqData
              DRA_rSR_WarningDisplay_WarningDisplayData: accessed-variable=rSR_WarningDisplay.WarningDisplayData
              DRA_rSR_WarningExtDisplay_WarningExtDisplayData: accessed-variable=rSR_WarningExtDisplay.WarningExtDisplayData
              DRA_rSR_DLTControlMessageReponse_DLTControlMessageReponseData: accessed-variable=rSR_DLTControlMessageReponse.DLTControlMessageReponseData
              DRA_rSR_DLTMessageReadRequest_DLTMessageReadRequestData: accessed-variable=rSR_DLTMessageReadRequest.DLTMessageReadRequestData
          data-send-points:
            19 x access:
              DSP_pSR_DiagResponse_DiagResponseData: accessed-variable=pSR_DiagResponse.DiagResponseData
              DWA_pSR_DisplayCurrentState_DisplayCurrentStateData: accessed-variable=pSR_DisplayCurrentState.DisplayCurrentStateData
              DWA_pSR_EmmcErrorNotifier_EmmcErrorNotifierData: accessed-variable=pSR_EmmcErrorNotifier.EmmcErrorNotifierData
              DSP_pSR_HealthDomainFatalError_HealthDomainFatalErrorData: accessed-variable=pSR_HealthDomainFatalError.HealthDomainFatalErrorData
              DSP_pSR_HealthDomainHeartbeat_HealthDomainHeartbeatData: accessed-variable=pSR_HealthDomainHeartbeat.HealthDomainHeartbeatData
              DSP_pSR_HealthDumpData_HealthDumpDataData: accessed-variable=pSR_HealthDumpData.HealthDumpDataData
              DSP_pSR_HealthDumpHdrInfo_HealthDumpHdrInfoData: accessed-variable=pSR_HealthDumpHdrInfo.HealthDumpHdrInfoData
              DSP_pSR_HealthEventRecord_HealthEventRecordData: accessed-variable=pSR_HealthEventRecord.HealthEventRecordData
              DWA_pSR_HudWarningStatus_HudWarningStatusData: accessed-variable=pSR_HudWarningStatus.HudWarningStatusData
              DSP_pSR_MainHMIReadyStatus_MainHMIReadyStatusData: accessed-variable=pSR_MainHMIReadyStatus.MainHMIReadyStatusData
              DSP_pSR_PowerExtendShutdownTime_PowerExtendShutdownTimeData: accessed-variable=pSR_PowerExtendShutdownTime.PowerExtendShutdownTimeData
              DSP_pSR_PowerKeepSystemAwake_PowerKeepSystemAwakeData: accessed-variable=pSR_PowerKeepSystemAwake.PowerKeepSystemAwakeData
              DWA_pSR_PowerSystemState_PowerSystemStateData: accessed-variable=pSR_PowerSystemState.PowerSystemStateData
              DSP_pSR_SafeHMIReadyStatus_SafeHMIReadyStatusData: accessed-variable=pSR_SafeHMIReadyStatus.SafeHMIReadyStatusData
              DSP_pSR_UpdateShortServiceResp_UpdateShortServiceRespData: accessed-variable=pSR_UpdateShortServiceResp.UpdateShortServiceRespData
              DWA_pSR_WarningDisplayAvailable_WarningDisplayAvailableData: accessed-variable=pSR_WarningDisplayAvailable.WarningDisplayAvailableData
              DWA_pSR_WarningStatus_WarningStatusData: accessed-variable=pSR_WarningStatus.WarningStatusData
              DWA_pSR_DLTControlMessageRequest_DLTControlMessageRequestData: accessed-variable=pSR_DLTControlMessageRequest.DLTControlMessageRequestData
              DWA_pSR_DLTMessageReadAck_DLTMessageReadAckData: accessed-variable=pSR_DLTMessageReadAck.DLTMessageReadAckData
          sync call OA_rCS_UclSystemCallbacks_ErrorNotification: operation=rCS_UclSystemCallbacks.ErrorNotification
          sync call OA_rCS_UclSystemCallbacks_LinkStatusChanged: operation=rCS_UclSystemCallbacks.LinkStatusChanged
        OnDre_DLTControlMessageReponse
          data-receive-point-by-arguments:
            25 x access:
              DRA_rSR_DLTControlMessageReponse_DLTControlMessageReponseData: accessed-variable=rSR_DLTControlMessageReponse.DLTControlMessageReponseData
              DRA_rSR_DLTMessageReadRequest_DLTMessageReadRequestData: accessed-variable=rSR_DLTMessageReadRequest.DLTMessageReadRequestData
              DRP_rSR_DiagDIDRequest_DiagDIDRequestData: accessed-variable=rSR_DiagDIDRequest.DiagDIDRequestData
              DRP_rSR_DiagIOCtrlRequest_DiagIOCtrlRequestData: accessed-variable=rSR_DiagIOCtrlRequest.DiagIOCtrlRequestData
              DRP_rSR_DiagRoutineRequest_DiagRoutineRequestData: accessed-variable=rSR_DiagRoutineRequest.DiagRoutineRequestData
              DRA_rSR_DisplaySetPower_DisplaySetPowerData: accessed-variable=rSR_DisplaySetPower.DisplaySetPowerData
              DRA_rSR_FRTT_Status_FRTT_StatusData: accessed-variable=rSR_FRTT_Status.FRTT_StatusData
              DRA_rSR_FastGaugeInfo_FastGaugeInfoData: accessed-variable=rSR_FastGaugeInfo.FastGaugeInfoData
              DRP_rSR_HealthDumpGetData_HealthDumpGetDataData: accessed-variable=rSR_HealthDumpGetData.HealthDumpGetDataData
              DRP_rSR_HealthDumpGetHdr_HealthDumpGetHdrData: accessed-variable=rSR_HealthDumpGetHdr.HealthDumpGetHdrData
              DRA_rSR_HudWarningDisplay_HudWarningDisplayData: accessed-variable=rSR_HudWarningDisplay.HudWarningDisplayData
              DRP_rSR_IgnState_IgnStateData: accessed-variable=rSR_IgnState.IgnStateData
              DRA_rSR_IlluminationData_IlluminationDataData: accessed-variable=rSR_IlluminationData.IlluminationDataData
              DRA_rSR_PowerSystemStateReqChange_PowerSystemStateReqChangeData: accessed-variable=rSR_PowerSystemStateReqChange.PowerSystemStateReqChangeData
              DRA_rSR_RTT_Icon_RTT_IconData: accessed-variable=rSR_RTT_Icon.RTT_IconData
              DRA_rSR_RTT_Status_RTT_StatusData: accessed-variable=rSR_RTT_Status.RTT_StatusData
              DRA_rSR_RTT_Toggle_RTT_ToggleData: accessed-variable=rSR_RTT_Toggle.RTT_ToggleData
              DRA_rSR_ShiftPosIndStatus_ShiftPosIndStatusData: accessed-variable=rSR_ShiftPosIndStatus.ShiftPosIndStatusData
              DRA_rSR_SlowGaugeInfo_SlowGaugeInfoData: accessed-variable=rSR_SlowGaugeInfo.SlowGaugeInfoData
              DRA_rSR_TT_Status_TT_StatusData: accessed-variable=rSR_TT_Status.TT_StatusData
              DRA_rSR_TpmsWarningData_TpmsWarningDataData: accessed-variable=rSR_TpmsWarningData.TpmsWarningDataData
              DRP_rSR_UpdateLongServiceReq_UpdateLongServiceReqData: accessed-variable=rSR_UpdateLongServiceReq.UpdateLongServiceReqData
              DRP_rSR_UpdateShortServiceReq_UpdateShortServiceReqData: accessed-variable=rSR_UpdateShortServiceReq.UpdateShortServiceReqData
              DRA_rSR_WarningDisplay_WarningDisplayData: accessed-variable=rSR_WarningDisplay.WarningDisplayData
              DRA_rSR_WarningExtDisplay_WarningExtDisplayData: accessed-variable=rSR_WarningExtDisplay.WarningExtDisplayData
          data-send-points:
            19 x access:
              DWA_pSR_DLTControlMessageRequest_DLTControlMessageRequestData: accessed-variable=pSR_DLTControlMessageRequest.DLTControlMessageRequestData
              DSP_pSR_DiagResponse_DiagResponseData: accessed-variable=pSR_DiagResponse.DiagResponseData
              DWA_pSR_DisplayCurrentState_DisplayCurrentStateData: accessed-variable=pSR_DisplayCurrentState.DisplayCurrentStateData
              DWA_pSR_EmmcErrorNotifier_EmmcErrorNotifierData: accessed-variable=pSR_EmmcErrorNotifier.EmmcErrorNotifierData
              DSP_pSR_HealthDomainFatalError_HealthDomainFatalErrorData: accessed-variable=pSR_HealthDomainFatalError.HealthDomainFatalErrorData
              DSP_pSR_HealthDomainHeartbeat_HealthDomainHeartbeatData: accessed-variable=pSR_HealthDomainHeartbeat.HealthDomainHeartbeatData
              DSP_pSR_HealthDumpData_HealthDumpDataData: accessed-variable=pSR_HealthDumpData.HealthDumpDataData
              DSP_pSR_HealthDumpHdrInfo_HealthDumpHdrInfoData: accessed-variable=pSR_HealthDumpHdrInfo.HealthDumpHdrInfoData
              DSP_pSR_HealthEventRecord_HealthEventRecordData: accessed-variable=pSR_HealthEventRecord.HealthEventRecordData
              DWA_pSR_HudWarningStatus_HudWarningStatusData: accessed-variable=pSR_HudWarningStatus.HudWarningStatusData
              DSP_pSR_MainHMIReadyStatus_MainHMIReadyStatusData: accessed-variable=pSR_MainHMIReadyStatus.MainHMIReadyStatusData
              DSP_pSR_PowerExtendShutdownTime_PowerExtendShutdownTimeData: accessed-variable=pSR_PowerExtendShutdownTime.PowerExtendShutdownTimeData
              DSP_pSR_PowerKeepSystemAwake_PowerKeepSystemAwakeData: accessed-variable=pSR_PowerKeepSystemAwake.PowerKeepSystemAwakeData
              DWA_pSR_PowerSystemState_PowerSystemStateData: accessed-variable=pSR_PowerSystemState.PowerSystemStateData
              DSP_pSR_SafeHMIReadyStatus_SafeHMIReadyStatusData: accessed-variable=pSR_SafeHMIReadyStatus.SafeHMIReadyStatusData
              DSP_pSR_UpdateShortServiceResp_UpdateShortServiceRespData: accessed-variable=pSR_UpdateShortServiceResp.UpdateShortServiceRespData
              DWA_pSR_WarningDisplayAvailable_WarningDisplayAvailableData: accessed-variable=pSR_WarningDisplayAvailable.WarningDisplayAvailableData
              DWA_pSR_WarningStatus_WarningStatusData: accessed-variable=pSR_WarningStatus.WarningStatusData
              DWA_pSR_DLTMessageReadAck_DLTMessageReadAckData: accessed-variable=pSR_DLTMessageReadAck.DLTMessageReadAckData
          sync call OA_rCS_UclSystemCallbacks_ErrorNotification: operation=rCS_UclSystemCallbacks.ErrorNotification
          sync call OA_rCS_UclSystemCallbacks_LinkStatusChanged: operation=rCS_UclSystemCallbacks.LinkStatusChanged
        OnDre_DLTMessageReadRequest
          data-receive-point-by-arguments:
            25 x access:
              DRA_rSR_DLTControlMessageReponse_DLTControlMessageReponseData: accessed-variable=rSR_DLTControlMessageReponse.DLTControlMessageReponseData
              DRA_rSR_DLTMessageReadRequest_DLTMessageReadRequestData: accessed-variable=rSR_DLTMessageReadRequest.DLTMessageReadRequestData
              DRP_rSR_DiagDIDRequest_DiagDIDRequestData: accessed-variable=rSR_DiagDIDRequest.DiagDIDRequestData
              DRP_rSR_DiagIOCtrlRequest_DiagIOCtrlRequestData: accessed-variable=rSR_DiagIOCtrlRequest.DiagIOCtrlRequestData
              DRP_rSR_DiagRoutineRequest_DiagRoutineRequestData: accessed-variable=rSR_DiagRoutineRequest.DiagRoutineRequestData
              DRA_rSR_DisplaySetPower_DisplaySetPowerData: accessed-variable=rSR_DisplaySetPower.DisplaySetPowerData
              DRA_rSR_FRTT_Status_FRTT_StatusData: accessed-variable=rSR_FRTT_Status.FRTT_StatusData
              DRA_rSR_FastGaugeInfo_FastGaugeInfoData: accessed-variable=rSR_FastGaugeInfo.FastGaugeInfoData
              DRP_rSR_HealthDumpGetData_HealthDumpGetDataData: accessed-variable=rSR_HealthDumpGetData.HealthDumpGetDataData
              DRP_rSR_HealthDumpGetHdr_HealthDumpGetHdrData: accessed-variable=rSR_HealthDumpGetHdr.HealthDumpGetHdrData
              DRA_rSR_HudWarningDisplay_HudWarningDisplayData: accessed-variable=rSR_HudWarningDisplay.HudWarningDisplayData
              DRP_rSR_IgnState_IgnStateData: accessed-variable=rSR_IgnState.IgnStateData
              DRA_rSR_IlluminationData_IlluminationDataData: accessed-variable=rSR_IlluminationData.IlluminationDataData
              DRA_rSR_PowerSystemStateReqChange_PowerSystemStateReqChangeData: accessed-variable=rSR_PowerSystemStateReqChange.PowerSystemStateReqChangeData
              DRA_rSR_RTT_Icon_RTT_IconData: accessed-variable=rSR_RTT_Icon.RTT_IconData
              DRA_rSR_RTT_Status_RTT_StatusData: accessed-variable=rSR_RTT_Status.RTT_StatusData
              DRA_rSR_RTT_Toggle_RTT_ToggleData: accessed-variable=rSR_RTT_Toggle.RTT_ToggleData
              DRA_rSR_ShiftPosIndStatus_ShiftPosIndStatusData: accessed-variable=rSR_ShiftPosIndStatus.ShiftPosIndStatusData
              DRA_rSR_SlowGaugeInfo_SlowGaugeInfoData: accessed-variable=rSR_SlowGaugeInfo.SlowGaugeInfoData
              DRA_rSR_TT_Status_TT_StatusData: accessed-variable=rSR_TT_Status.TT_StatusData
              DRA_rSR_TpmsWarningData_TpmsWarningDataData: accessed-variable=rSR_TpmsWarningData.TpmsWarningDataData
              DRP_rSR_UpdateLongServiceReq_UpdateLongServiceReqData: accessed-variable=rSR_UpdateLongServiceReq.UpdateLongServiceReqData
              DRP_rSR_UpdateShortServiceReq_UpdateShortServiceReqData: accessed-variable=rSR_UpdateShortServiceReq.UpdateShortServiceReqData
              DRA_rSR_WarningDisplay_WarningDisplayData: accessed-variable=rSR_WarningDisplay.WarningDisplayData
              DRA_rSR_WarningExtDisplay_WarningExtDisplayData: accessed-variable=rSR_WarningExtDisplay.WarningExtDisplayData
          data-send-points:
            19 x access:
              DWA_pSR_DLTControlMessageRequest_DLTControlMessageRequestData: accessed-variable=pSR_DLTControlMessageRequest.DLTControlMessageRequestData
              DSP_pSR_DiagResponse_DiagResponseData: accessed-variable=pSR_DiagResponse.DiagResponseData
              DWA_pSR_DisplayCurrentState_DisplayCurrentStateData: accessed-variable=pSR_DisplayCurrentState.DisplayCurrentStateData
              DWA_pSR_EmmcErrorNotifier_EmmcErrorNotifierData: accessed-variable=pSR_EmmcErrorNotifier.EmmcErrorNotifierData
              DSP_pSR_HealthDomainFatalError_HealthDomainFatalErrorData: accessed-variable=pSR_HealthDomainFatalError.HealthDomainFatalErrorData
              DSP_pSR_HealthDomainHeartbeat_HealthDomainHeartbeatData: accessed-variable=pSR_HealthDomainHeartbeat.HealthDomainHeartbeatData
              DSP_pSR_HealthDumpData_HealthDumpDataData: accessed-variable=pSR_HealthDumpData.HealthDumpDataData
              DSP_pSR_HealthDumpHdrInfo_HealthDumpHdrInfoData: accessed-variable=pSR_HealthDumpHdrInfo.HealthDumpHdrInfoData
              DSP_pSR_HealthEventRecord_HealthEventRecordData: accessed-variable=pSR_HealthEventRecord.HealthEventRecordData
              DWA_pSR_HudWarningStatus_HudWarningStatusData: accessed-variable=pSR_HudWarningStatus.HudWarningStatusData
              DSP_pSR_MainHMIReadyStatus_MainHMIReadyStatusData: accessed-variable=pSR_MainHMIReadyStatus.MainHMIReadyStatusData
              DSP_pSR_PowerExtendShutdownTime_PowerExtendShutdownTimeData: accessed-variable=pSR_PowerExtendShutdownTime.PowerExtendShutdownTimeData
              DSP_pSR_PowerKeepSystemAwake_PowerKeepSystemAwakeData: accessed-variable=pSR_PowerKeepSystemAwake.PowerKeepSystemAwakeData
              DWA_pSR_PowerSystemState_PowerSystemStateData: accessed-variable=pSR_PowerSystemState.PowerSystemStateData
              DSP_pSR_SafeHMIReadyStatus_SafeHMIReadyStatusData: accessed-variable=pSR_SafeHMIReadyStatus.SafeHMIReadyStatusData
              DSP_pSR_UpdateShortServiceResp_UpdateShortServiceRespData: accessed-variable=pSR_UpdateShortServiceResp.UpdateShortServiceRespData
              DWA_pSR_WarningDisplayAvailable_WarningDisplayAvailableData: accessed-variable=pSR_WarningDisplayAvailable.WarningDisplayAvailableData
              DWA_pSR_WarningStatus_WarningStatusData: accessed-variable=pSR_WarningStatus.WarningStatusData
              DWA_pSR_DLTMessageReadAck_DLTMessageReadAckData: accessed-variable=pSR_DLTMessageReadAck.DLTMessageReadAckData
          sync call OA_rCS_UclSystemCallbacks_ErrorNotification: operation=rCS_UclSystemCallbacks.ErrorNotification
          sync call OA_rCS_UclSystemCallbacks_LinkStatusChanged: operation=rCS_UclSystemCallbacks.LinkStatusChanged
  swc implementation IMPL_UclProxyCdd: behavior=IB_UclProxyCdd
    code-descriptors:
      code Default: artifact-descriptors=autosar-engineering-object=category=SWSRC
